AUTOSAR XML (schema 4-2-2)
package /UAES/ASW
  swc implementation Implementation: programming-language=C, sw-version=1.258.1, used-code-generator=Embedded Coder 7.1 (R2018b) 24-May-2018, vendor-id=0, behavior=InternalBehavior
    code-descriptors:
      code Code
        artifact-descriptors:
          short-label=Win_Ctrl_c, category=SWSRC
          short-label=plook_u32u8_even0cka_c, category=SWSRC
          short-label=Win_Ctrl_h, category=SWHDR
          short-label=plook_u32u8_even0cka_h, category=SWHDR
          short-label=rtwtypes_h, category=SWHDR
    resource consumption RsrcCons_Win_Ctrl
package /UAES/ASW/SwComponentTypes
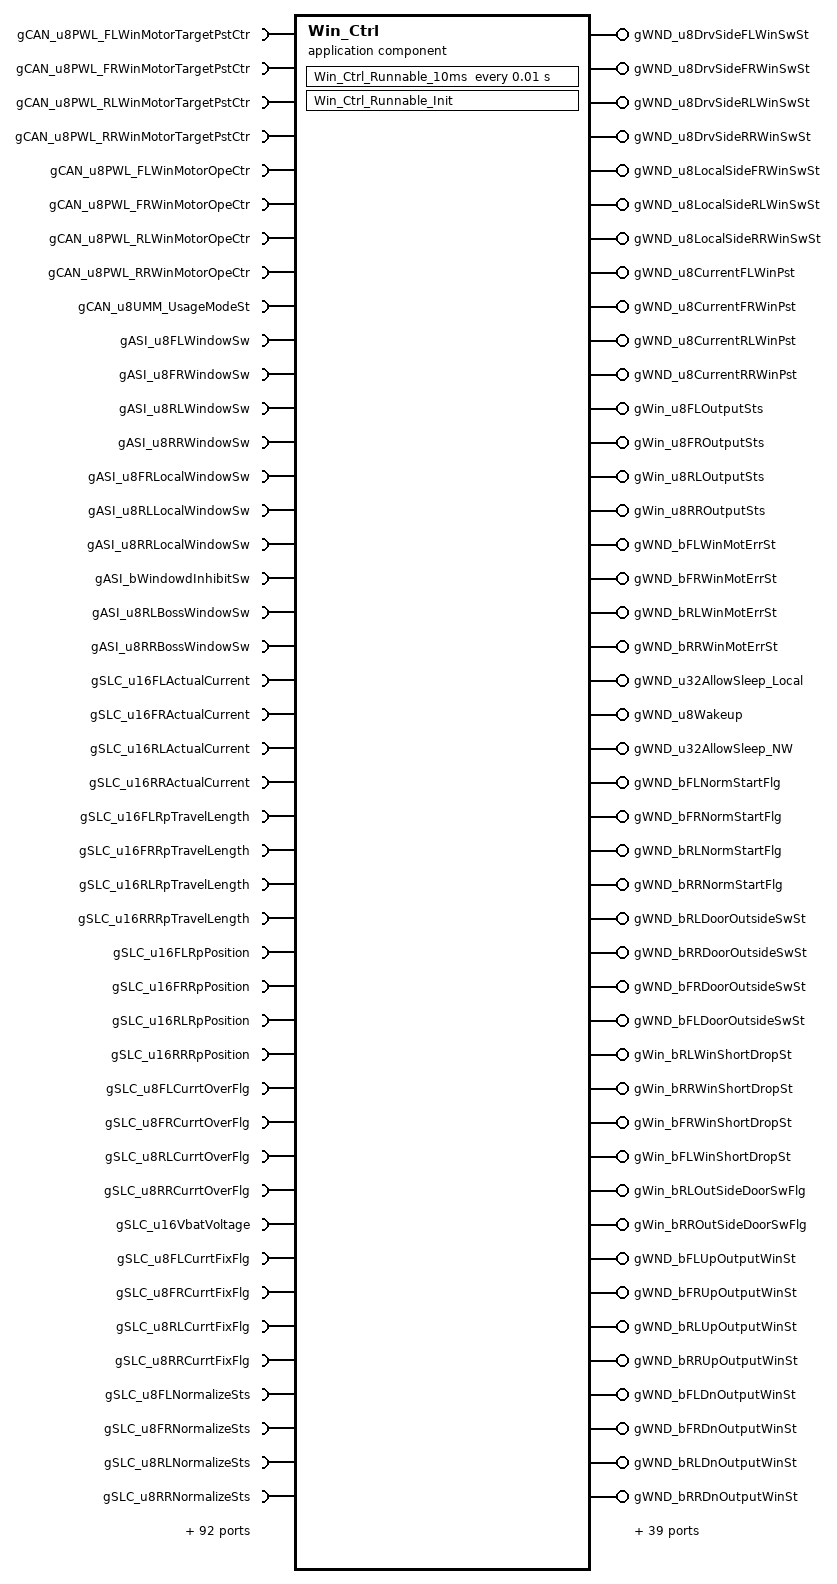
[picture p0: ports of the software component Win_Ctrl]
  application sw component type Win_Ctrl
    136 x require port:
      gCAN_u8PWL_FLWinMotorTargetPstCtr: nonqueued-receiver-com-spec{data-element=gCAN_u8PWL_FLWinMotorTargetPstCtr/Val, init-value=0}, required-interface=gCAN_u8PWL_FLWinMotorTargetPstCtr
      gCAN_u8PWL_FRWinMotorTargetPstCtr: nonqueued-receiver-com-spec{data-element=gCAN_u8PWL_FRWinMotorTargetPstCtr/Val, init-value=0}, required-interface=gCAN_u8PWL_FRWinMotorTargetPstCtr
      gCAN_u8PWL_RLWinMotorTargetPstCtr: nonqueued-receiver-com-spec{data-element=gCAN_u8PWL_RLWinMotorTargetPstCtr/Val, init-value=0}, required-interface=gCAN_u8PWL_RLWinMotorTargetPstCtr
      gCAN_u8PWL_RRWinMotorTargetPstCtr: nonqueued-receiver-com-spec{data-element=gCAN_u8PWL_RRWinMotorTargetPstCtr/Val, init-value=0}, required-interface=gCAN_u8PWL_RRWinMotorTargetPstCtr
      gCAN_u8PWL_FLWinMotorOpeCtr: nonqueued-receiver-com-spec{data-element=gCAN_u8PWL_FLWinMotorOpeCtr/Val, init-value=0}, required-interface=gCAN_u8PWL_FLWinMotorOpeCtr
      gCAN_u8PWL_FRWinMotorOpeCtr: nonqueued-receiver-com-spec{data-element=gCAN_u8PWL_FRWinMotorOpeCtr/Val, init-value=0}, required-interface=gCAN_u8PWL_FRWinMotorOpeCtr
      gCAN_u8PWL_RLWinMotorOpeCtr: nonqueued-receiver-com-spec{data-element=gCAN_u8PWL_RLWinMotorOpeCtr/Val, init-value=0}, required-interface=gCAN_u8PWL_RLWinMotorOpeCtr
      gCAN_u8PWL_RRWinMotorOpeCtr: nonqueued-receiver-com-spec{data-element=gCAN_u8PWL_RRWinMotorOpeCtr/Val, init-value=0}, required-interface=gCAN_u8PWL_RRWinMotorOpeCtr
      gCAN_u8UMM_UsageModeSt: nonqueued-receiver-com-spec{data-element=gCAN_u8UMM_UsageModeSt/Val, init-value=0}, required-interface=gCAN_u8UMM_UsageModeSt
      gASI_u8FLWindowSw: nonqueued-receiver-com-spec{data-element=gASI_u8FLWindowSw/Val, init-value=0}, required-interface=gASI_u8FLWindowSw
      gASI_u8FRWindowSw: nonqueued-receiver-com-spec{data-element=gASI_u8FRWindowSw/Val, init-value=0}, required-interface=gASI_u8FRWindowSw
      gASI_u8RLWindowSw: nonqueued-receiver-com-spec{data-element=gASI_u8RLWindowSw/Val, init-value=0}, required-interface=gASI_u8RLWindowSw
      gASI_u8RRWindowSw: nonqueued-receiver-com-spec{data-element=gASI_u8RRWindowSw/Val, init-value=0}, required-interface=gASI_u8RRWindowSw
      gASI_u8FRLocalWindowSw: nonqueued-receiver-com-spec{data-element=gASI_u8FRLocalWindowSw/Val, init-value=0}, required-interface=gASI_u8FRLocalWindowSw
      gASI_u8RLLocalWindowSw: nonqueued-receiver-com-spec{data-element=gASI_u8RLLocalWindowSw/Val, init-value=0}, required-interface=gASI_u8RLLocalWindowSw
      gASI_u8RRLocalWindowSw: nonqueued-receiver-com-spec{data-element=gASI_u8RRLocalWindowSw/Val, init-value=0}, required-interface=gASI_u8RRLocalWindowSw
      gASI_bWindowdInhibitSw: nonqueued-receiver-com-spec{data-element=gASI_bWindowdInhibitSw/Val, init-value=0}, required-interface=gASI_bWindowdInhibitSw
      gASI_u8RLBossWindowSw: nonqueued-receiver-com-spec{data-element=gASI_u8RLBossWindowSw/Val, init-value=0}, required-interface=gASI_u8RLBossWindowSw
      gASI_u8RRBossWindowSw: nonqueued-receiver-com-spec{data-element=gASI_u8RRBossWindowSw/Val, init-value=0}, required-interface=gASI_u8RRBossWindowSw
      gSLC_u16FLActualCurrent: nonqueued-receiver-com-spec{data-element=gSLC_u16FLActualCurrent/Val, init-value=0}, required-interface=gSLC_u16FLActualCurrent
      gSLC_u16FRActualCurrent: nonqueued-receiver-com-spec{data-element=gSLC_u16FRActualCurrent/Val, init-value=0}, required-interface=gSLC_u16FRActualCurrent
      gSLC_u16RLActualCurrent: nonqueued-receiver-com-spec{data-element=gSLC_u16RLActualCurrent/Val, init-value=0}, required-interface=gSLC_u16RLActualCurrent
      gSLC_u16RRActualCurrent: nonqueued-receiver-com-spec{data-element=gSLC_u16RRActualCurrent/Val, init-value=0}, required-interface=gSLC_u16RRActualCurrent
      gSLC_u16FLRpTravelLength: nonqueued-receiver-com-spec{data-element=gSLC_u16FLRpTravelLength/Val, init-value=0}, required-interface=gSLC_u16FLRpTravelLength
      gSLC_u16FRRpTravelLength: nonqueued-receiver-com-spec{data-element=gSLC_u16FRRpTravelLength/Val, init-value=0}, required-interface=gSLC_u16FRRpTravelLength
      gSLC_u16RLRpTravelLength: nonqueued-receiver-com-spec{data-element=gSLC_u16RLRpTravelLength/Val, init-value=0}, required-interface=gSLC_u16RLRpTravelLength
      gSLC_u16RRRpTravelLength: nonqueued-receiver-com-spec{data-element=gSLC_u16RRRpTravelLength/Val, init-value=0}, required-interface=gSLC_u16RRRpTravelLength
      gSLC_u16FLRpPosition: nonqueued-receiver-com-spec{data-element=gSLC_u16FLRpPosition/Val, init-value=0}, required-interface=gSLC_u16FLRpPosition
      gSLC_u16FRRpPosition: nonqueued-receiver-com-spec{data-element=gSLC_u16FRRpPosition/Val, init-value=0}, required-interface=gSLC_u16FRRpPosition
      gSLC_u16RLRpPosition: nonqueued-receiver-com-spec{data-element=gSLC_u16RLRpPosition/Val, init-value=0}, required-interface=gSLC_u16RLRpPosition
      gSLC_u16RRRpPosition: nonqueued-receiver-com-spec{data-element=gSLC_u16RRRpPosition/Val, init-value=0}, required-interface=gSLC_u16RRRpPosition
      gSLC_u8FLCurrtOverFlg: nonqueued-receiver-com-spec{data-element=gSLC_u8FLCurrtOverFlg/Val, init-value=0}, required-interface=gSLC_u8FLCurrtOverFlg
      gSLC_u8FRCurrtOverFlg: nonqueued-receiver-com-spec{data-element=gSLC_u8FRCurrtOverFlg/Val, init-value=0}, required-interface=gSLC_u8FRCurrtOverFlg
      gSLC_u8RLCurrtOverFlg: nonqueued-receiver-com-spec{data-element=gSLC_u8RLCurrtOverFlg/Val, init-value=0}, required-interface=gSLC_u8RLCurrtOverFlg
      gSLC_u8RRCurrtOverFlg: nonqueued-receiver-com-spec{data-element=gSLC_u8RRCurrtOverFlg/Val, init-value=0}, required-interface=gSLC_u8RRCurrtOverFlg
      gSLC_u16VbatVoltage: nonqueued-receiver-com-spec{data-element=gSLC_u16VbatVoltage/Val, init-value=0}, required-interface=gSLC_u16VbatVoltage
      gSLC_u8FLCurrtFixFlg: nonqueued-receiver-com-spec{data-element=gSLC_u8FLCurrtFixFlg/Val, init-value=0}, required-interface=gSLC_u8FLCurrtFixFlg
      gSLC_u8FRCurrtFixFlg: nonqueued-receiver-com-spec{data-element=gSLC_u8FRCurrtFixFlg/Val, init-value=0}, required-interface=gSLC_u8FRCurrtFixFlg
      gSLC_u8RLCurrtFixFlg: nonqueued-receiver-com-spec{data-element=gSLC_u8RLCurrtFixFlg/Val, init-value=0}, required-interface=gSLC_u8RLCurrtFixFlg
      gSLC_u8RRCurrtFixFlg: nonqueued-receiver-com-spec{data-element=gSLC_u8RRCurrtFixFlg/Val, init-value=0}, required-interface=gSLC_u8RRCurrtFixFlg
      gSLC_u8FLNormalizeSts: nonqueued-receiver-com-spec{data-element=gSLC_u8FLNormalizeSts/Val, init-value=0}, required-interface=gSLC_u8FLNormalizeSts
      gSLC_u8FRNormalizeSts: nonqueued-receiver-com-spec{data-element=gSLC_u8FRNormalizeSts/Val, init-value=0}, required-interface=gSLC_u8FRNormalizeSts
      gSLC_u8RLNormalizeSts: nonqueued-receiver-com-spec{data-element=gSLC_u8RLNormalizeSts/Val, init-value=0}, required-interface=gSLC_u8RLNormalizeSts
      gSLC_u8RRNormalizeSts: nonqueued-receiver-com-spec{data-element=gSLC_u8RRNormalizeSts/Val, init-value=0}, required-interface=gSLC_u8RRNormalizeSts
      gSLC_bFLAPHappen: nonqueued-receiver-com-spec{data-element=gSLC_bFLAPHappen/Val, init-value=0}, required-interface=gSLC_bFLAPHappen
      gSLC_bFRAPHappen: nonqueued-receiver-com-spec{data-element=gSLC_bFRAPHappen/Val, init-value=0}, required-interface=gSLC_bFRAPHappen
      gSLC_bRLAPHappen: nonqueued-receiver-com-spec{data-element=gSLC_bRLAPHappen/Val, init-value=0}, required-interface=gSLC_bRLAPHappen
      gSLC_bRRAPHappen: nonqueued-receiver-com-spec{data-element=gSLC_bRRAPHappen/Val, init-value=0}, required-interface=gSLC_bRRAPHappen
      gSLC_bFLTDCSStopReq: nonqueued-receiver-com-spec{data-element=gSLC_bFLTDCSStopReq/Val, init-value=0}, required-interface=gSLC_bFLTDCSStopReq
      gSLC_bFRTDCSStopReq: nonqueued-receiver-com-spec{data-element=gSLC_bFRTDCSStopReq/Val, init-value=0}, required-interface=gSLC_bFRTDCSStopReq
      gSLC_bRLTDCSStopReq: nonqueued-receiver-com-spec{data-element=gSLC_bRLTDCSStopReq/Val, init-value=0}, required-interface=gSLC_bRLTDCSStopReq
      gSLC_bRRTDCSStopReq: nonqueued-receiver-com-spec{data-element=gSLC_bRRTDCSStopReq/Val, init-value=0}, required-interface=gSLC_bRRTDCSStopReq
      gSLC_bFLBDCSStopReq: nonqueued-receiver-com-spec{data-element=gSLC_bFLBDCSStopReq/Val, init-value=0}, required-interface=gSLC_bFLBDCSStopReq
      gSLC_bFRBDCSStopReq: nonqueued-receiver-com-spec{data-element=gSLC_bFRBDCSStopReq/Val, init-value=0}, required-interface=gSLC_bFRBDCSStopReq
      gSLC_bRLBDCSStopReq: nonqueued-receiver-com-spec{data-element=gSLC_bRLBDCSStopReq/Val, init-value=0}, required-interface=gSLC_bRLBDCSStopReq
      gSLC_bRRBDCSStopReq: nonqueued-receiver-com-spec{data-element=gSLC_bRRBDCSStopReq/Val, init-value=0}, required-interface=gSLC_bRRBDCSStopReq
      gSLC_bFLIsInAPRange: nonqueued-receiver-com-spec{data-element=gSLC_bFLIsInAPRange/Val, init-value=0}, required-interface=gSLC_bFLIsInAPRange
      gSLC_bFRIsInAPRange: nonqueued-receiver-com-spec{data-element=gSLC_bFRIsInAPRange/Val, init-value=0}, required-interface=gSLC_bFRIsInAPRange
      gSLC_bRLIsInAPRange: nonqueued-receiver-com-spec{data-element=gSLC_bRLIsInAPRange/Val, init-value=0}, required-interface=gSLC_bRLIsInAPRange
      gSLC_bRRIsInAPRange: nonqueued-receiver-com-spec{data-element=gSLC_bRRIsInAPRange/Val, init-value=0}, required-interface=gSLC_bRRIsInAPRange
      gSLC_bFLPositionLostFlg: nonqueued-receiver-com-spec{data-element=gSLC_bFLPositionLostFlg/Val, init-value=0}, required-interface=gSLC_bFLPositionLostFlg
      gSLC_bFRPositionLostFlg: nonqueued-receiver-com-spec{data-element=gSLC_bFRPositionLostFlg/Val, init-value=0}, required-interface=gSLC_bFRPositionLostFlg
      gSLC_bRLPositionLostFlg: nonqueued-receiver-com-spec{data-element=gSLC_bRLPositionLostFlg/Val, init-value=0}, required-interface=gSLC_bRLPositionLostFlg
      gSLC_bRRPositionLostFlg: nonqueued-receiver-com-spec{data-element=gSLC_bRRPositionLostFlg/Val, init-value=0}, required-interface=gSLC_bRRPositionLostFlg
      gDoor_bFLDoorAjarSt: nonqueued-receiver-com-spec{data-element=gDoor_bFLDoorAjarSt/Val, init-value=0}, required-interface=gDoor_bFLDoorAjarSt
      gDoor_bFRDoorAjarSt: nonqueued-receiver-com-spec{data-element=gDoor_bFRDoorAjarSt/Val, init-value=0}, required-interface=gDoor_bFRDoorAjarSt
      gDoor_bRLDoorAjarSt: nonqueued-receiver-com-spec{data-element=gDoor_bRLDoorAjarSt/Val, init-value=0}, required-interface=gDoor_bRLDoorAjarSt
      gDoor_bRRDoorAjarSt: nonqueued-receiver-com-spec{data-element=gDoor_bRRDoorAjarSt/Val, init-value=0}, required-interface=gDoor_bRRDoorAjarSt
      gASI_bRLDoorHSUSw: nonqueued-receiver-com-spec{data-element=gASI_bRLDoorHSUSw/Val, init-value=0}, required-interface=gASI_bRLDoorHSUSw
      gASI_bRRDoorHSUSw: nonqueued-receiver-com-spec{data-element=gASI_bRRDoorHSUSw/Val, init-value=0}, required-interface=gASI_bRRDoorHSUSw
      gASI_bFLDoorHSUSw: nonqueued-receiver-com-spec{data-element=gASI_bFLDoorHSUSw/Val, init-value=0}, required-interface=gASI_bFLDoorHSUSw
      gASI_bFRDoorHSUSw: nonqueued-receiver-com-spec{data-element=gASI_bFRDoorHSUSw/Val, init-value=0}, required-interface=gASI_bFRDoorHSUSw
      gLock_bRLDoorLockFbSt: nonqueued-receiver-com-spec{data-element=gLock_bRLDoorLockFbSt/Val, init-value=0}, required-interface=gLock_bRLDoorLockFbSt
      gLock_bRRDoorLockFbSt: nonqueued-receiver-com-spec{data-element=gLock_bRRDoorLockFbSt/Val, init-value=0}, required-interface=gLock_bRRDoorLockFbSt
      gLock_bFLDoorLockFbSt: nonqueued-receiver-com-spec{data-element=gLock_bFLDoorLockFbSt/Val, init-value=0}, required-interface=gLock_bFLDoorLockFbSt
      gLock_bFRDoorLockFbSt: nonqueued-receiver-com-spec{data-element=gLock_bFRDoorLockFbSt/Val, init-value=0}, required-interface=gLock_bFRDoorLockFbSt
      gCFG_bFLDoorFramelessGlassCfg: nonqueued-receiver-com-spec{data-element=gCFG_bFLDoorFramelessGlassCfg/Val, init-value=0}, required-interface=gCFG_bFLDoorFramelessGlassCfg
      gCFG_bFRDoorFramelessGlassCfg: nonqueued-receiver-com-spec{data-element=gCFG_bFRDoorFramelessGlassCfg/Val, init-value=0}, required-interface=gCFG_bFRDoorFramelessGlassCfg
      gCFG_bRLDoorFramelessGlassCfg: nonqueued-receiver-com-spec{data-element=gCFG_bRLDoorFramelessGlassCfg/Val, init-value=0}, required-interface=gCFG_bRLDoorFramelessGlassCfg
      gCFG_bRRDoorFramelessGlassCfg: nonqueued-receiver-com-spec{data-element=gCFG_bRRDoorFramelessGlassCfg/Val, init-value=0}, required-interface=gCFG_bRRDoorFramelessGlassCfg
      gCAN_u8POD_FLWinShortDropCmd: nonqueued-receiver-com-spec{data-element=gCAN_u8POD_FLWinShortDropCmd/Val, init-value=0}, required-interface=gCAN_u8POD_FLWinShortDropCmd
      gCAN_u8POD_FRWinShortDropCmd: nonqueued-receiver-com-spec{data-element=gCAN_u8POD_FRWinShortDropCmd/Val, init-value=0}, required-interface=gCAN_u8POD_FRWinShortDropCmd
      gCAN_u8POD_RLWinShortDropCmd: nonqueued-receiver-com-spec{data-element=gCAN_u8POD_RLWinShortDropCmd/Val, init-value=0}, required-interface=gCAN_u8POD_RLWinShortDropCmd
      gCAN_u8POD_RRWinShortDropCmd: nonqueued-receiver-com-spec{data-element=gCAN_u8POD_RRWinShortDropCmd/Val, init-value=0}, required-interface=gCAN_u8POD_RRWinShortDropCmd
      gCFG_u8PwrRelsType: nonqueued-receiver-com-spec{data-element=gCFG_u8PwrRelsType/Val, init-value=0}, required-interface=gCFG_u8PwrRelsType
      gCFG_bWndVentilationFunCfg: nonqueued-receiver-com-spec{data-element=gCFG_bWndVentilationFunCfg/Val, init-value=0}, required-interface=gCFG_bWndVentilationFunCfg
      gPRM_u8WndVentilationPst: nonqueued-receiver-com-spec{data-element=gPRM_u8WndVentilationPst/Val, init-value=0}, required-interface=gPRM_u8WndVentilationPst
      gPRM_u8WndLckLEDPWM_Lv1: nonqueued-receiver-com-spec{data-element=gPRM_u8WndLckLEDPWM_Lv1/Val, init-value=0}, required-interface=gPRM_u8WndLckLEDPWM_Lv1
      gPRM_u8WndLckLEDPWM_Lv2: nonqueued-receiver-com-spec{data-element=gPRM_u8WndLckLEDPWM_Lv2/Val, init-value=0}, required-interface=gPRM_u8WndLckLEDPWM_Lv2
      gPRM_u8FLWinShortDropPst: nonqueued-receiver-com-spec{data-element=gPRM_u8FLWinShortDropPst/Val, init-value=0}, required-interface=gPRM_u8FLWinShortDropPst
      gPRM_u8FRWinShortDropPst: nonqueued-receiver-com-spec{data-element=gPRM_u8FRWinShortDropPst/Val, init-value=0}, required-interface=gPRM_u8FRWinShortDropPst
      gPRM_u8RLWinShortDropPst: nonqueued-receiver-com-spec{data-element=gPRM_u8RLWinShortDropPst/Val, init-value=0}, required-interface=gPRM_u8RLWinShortDropPst
      gPRM_u8RRWinShortDropPst: nonqueued-receiver-com-spec{data-element=gPRM_u8RRWinShortDropPst/Val, init-value=0}, required-interface=gPRM_u8RRWinShortDropPst
      gPRM_u8FLPowerDoorReqWinOpenPst: nonqueued-receiver-com-spec{data-element=gPRM_u8FLPowerDoorReqWinOpenPst/Val, init-value=0}, required-interface=gPRM_u8FLPowerDoorReqWinOpenPst
      gPRM_u8FRPowerDoorReqWinOpenPst: nonqueued-receiver-com-spec{data-element=gPRM_u8FRPowerDoorReqWinOpenPst/Val, init-value=0}, required-interface=gPRM_u8FRPowerDoorReqWinOpenPst
      gPRM_u8RLPowerDoorReqWinOpenPst: nonqueued-receiver-com-spec{data-element=gPRM_u8RLPowerDoorReqWinOpenPst/Val, init-value=0}, required-interface=gPRM_u8RLPowerDoorReqWinOpenPst
      gPRM_u8RRPowerDoorReqWinOpenPst: nonqueued-receiver-com-spec{data-element=gPRM_u8RRPowerDoorReqWinOpenPst/Val, init-value=0}, required-interface=gPRM_u8RRPowerDoorReqWinOpenPst
      gPRM_bPODRelsCinchFunEnCfgFL: nonqueued-receiver-com-spec{data-element=gPRM_bPODRelsCinchFunEnCfgFL/Val, init-value=0}, required-interface=gPRM_bPODRelsCinchFunEnCfgFL
      gPRM_bPODRelsCinchFunEnCfgFR: nonqueued-receiver-com-spec{data-element=gPRM_bPODRelsCinchFunEnCfgFR/Val, init-value=0}, required-interface=gPRM_bPODRelsCinchFunEnCfgFR
      gPRM_bPODRelsCinchFunEnCfgRL: nonqueued-receiver-com-spec{data-element=gPRM_bPODRelsCinchFunEnCfgRL/Val, init-value=0}, required-interface=gPRM_bPODRelsCinchFunEnCfgRL
      gPRM_bPODRelsCinchFunEnCfgRR: nonqueued-receiver-com-spec{data-element=gPRM_bPODRelsCinchFunEnCfgRR/Val, init-value=0}, required-interface=gPRM_bPODRelsCinchFunEnCfgRR
      gDCU_bFLReverseFlag: nonqueued-receiver-com-spec{data-element=gDCU_bFLReverseFlag/Val, init-value=0}, required-interface=gDCU_bFLReverseFlag
      gDCU_bFRReverseFlag: nonqueued-receiver-com-spec{data-element=gDCU_bFRReverseFlag/Val, init-value=0}, required-interface=gDCU_bFRReverseFlag
      gDCU_bRLReverseFlag: nonqueued-receiver-com-spec{data-element=gDCU_bRLReverseFlag/Val, init-value=0}, required-interface=gDCU_bRLReverseFlag
      gDCU_bRRReverseFlag: nonqueued-receiver-com-spec{data-element=gDCU_bRRReverseFlag/Val, init-value=0}, required-interface=gDCU_bRRReverseFlag
      gASI_bCCULostCommon: nonqueued-receiver-com-spec{data-element=gASI_bCCULostCommon/Val, init-value=0}, required-interface=gASI_bCCULostCommon
      gASI_bPowerOnReset: nonqueued-receiver-com-spec{data-element=gASI_bPowerOnReset/Val, init-value=0}, required-interface=gASI_bPowerOnReset
      gVRM_u16BatteryVolt_mv: nonqueued-receiver-com-spec{data-element=gVRM_u16BatteryVolt_mv/Val, init-value=0}, required-interface=gVRM_u16BatteryVolt_mv
      gSLC_bFLActiveFlg: nonqueued-receiver-com-spec{data-element=gSLC_bFLActiveFlg/Val, init-value=0}, required-interface=gSLC_bFLActiveFlg
      gSLC_bFRActiveFlg: nonqueued-receiver-com-spec{data-element=gSLC_bFRActiveFlg/Val, init-value=0}, required-interface=gSLC_bFRActiveFlg
      gSLC_bRLActiveFlg: nonqueued-receiver-com-spec{data-element=gSLC_bRLActiveFlg/Val, init-value=0}, required-interface=gSLC_bRLActiveFlg
      gSLC_bRRActiveFlg: nonqueued-receiver-com-spec{data-element=gSLC_bRRActiveFlg/Val, init-value=0}, required-interface=gSLC_bRRActiveFlg
      gDCU_bFLWinUpOutput: nonqueued-receiver-com-spec{data-element=gDCU_bFLWinUpOutput/Val, init-value=0}, required-interface=gDCU_bFLWinUpOutput
      gDCU_bFLWinDownOutput: nonqueued-receiver-com-spec{data-element=gDCU_bFLWinDownOutput/Val, init-value=0}, required-interface=gDCU_bFLWinDownOutput
      gDCU_bFRWinUpOutput: nonqueued-receiver-com-spec{data-element=gDCU_bFRWinUpOutput/Val, init-value=0}, required-interface=gDCU_bFRWinUpOutput
      gDCU_bFRWinDownOutput: nonqueued-receiver-com-spec{data-element=gDCU_bFRWinDownOutput/Val, init-value=0}, required-interface=gDCU_bFRWinDownOutput
      gDCU_bRLWinUpOutput: nonqueued-receiver-com-spec{data-element=gDCU_bRLWinUpOutput/Val, init-value=0}, required-interface=gDCU_bRLWinUpOutput
      gDCU_bRLWinDownOutput: nonqueued-receiver-com-spec{data-element=gDCU_bRLWinDownOutput/Val, init-value=0}, required-interface=gDCU_bRLWinDownOutput
      gDCU_bRRWinUpOutput: nonqueued-receiver-com-spec{data-element=gDCU_bRRWinUpOutput/Val, init-value=0}, required-interface=gDCU_bRRWinUpOutput
      gDCU_bRRWinDownOutput: nonqueued-receiver-com-spec{data-element=gDCU_bRRWinDownOutput/Val, init-value=0}, required-interface=gDCU_bRRWinDownOutput
      gWin_bFLSwStuckFlg: nonqueued-receiver-com-spec{data-element=gWin_bFLSwStuckFlg/Val, init-value=0}, required-interface=gWin_bFLSwStuckFlg
      gWin_bFRSwStuckFlg: nonqueued-receiver-com-spec{data-element=gWin_bFRSwStuckFlg/Val, init-value=0}, required-interface=gWin_bFRSwStuckFlg
      gWin_bRLSwStuckFlg: nonqueued-receiver-com-spec{data-element=gWin_bRLSwStuckFlg/Val, init-value=0}, required-interface=gWin_bRLSwStuckFlg
      gWin_bRRSwStuckFlg: nonqueued-receiver-com-spec{data-element=gWin_bRRSwStuckFlg/Val, init-value=0}, required-interface=gWin_bRRSwStuckFlg
      gCAN_bPWL_FLWinRelearnReq: nonqueued-receiver-com-spec{data-element=gCAN_bPWL_FLWinRelearnReq/Val, init-value=0}, required-interface=gCAN_bPWL_FLWinRelearnReq
      gCAN_bPWL_FRWinRelearnReq: nonqueued-receiver-com-spec{data-element=gCAN_bPWL_FRWinRelearnReq/Val, init-value=0}, required-interface=gCAN_bPWL_FRWinRelearnReq
      gCAN_bPWL_RLWinRelearnReq: nonqueued-receiver-com-spec{data-element=gCAN_bPWL_RLWinRelearnReq/Val, init-value=0}, required-interface=gCAN_bPWL_RLWinRelearnReq
      gCAN_bPWL_RRWinRelearnReq: nonqueued-receiver-com-spec{data-element=gCAN_bPWL_RRWinRelearnReq/Val, init-value=0}, required-interface=gCAN_bPWL_RRWinRelearnReq
      gCFG_u8LocalSideWinSwType: nonqueued-receiver-com-spec{data-element=gCFG_u8LocalSideWinSwType/Val, init-value=0}, required-interface=gCFG_u8LocalSideWinSwType
      gCFG_u8DriverSideWinSwType: nonqueued-receiver-com-spec{data-element=gCFG_u8DriverSideWinSwType/Val, init-value=0}, required-interface=gCFG_u8DriverSideWinSwType
      gPRM_u8UINM_DriverSideWinSwActivetime: nonqueued-receiver-com-spec{data-element=gPRM_u8UINM_DriverSideWinSwActivetime/Val, init-value=0}, required-interface=gPRM_u8UINM_DriverSideWinSwActivetime
      gPRM_u8UINM_LocalSideWinSwActivetime: nonqueued-receiver-com-spec{data-element=gPRM_u8UINM_LocalSideWinSwActivetime/Val, init-value=0}, required-interface=gPRM_u8UINM_LocalSideWinSwActivetime
      gWND_u8DrvWinOutput: nonqueued-receiver-com-spec{data-element=gWND_u8DrvWinOutput/Val, init-value=0}, required-interface=gWND_u8DrvWinOutput
      gWND_u8PsgWinOutput: nonqueued-receiver-com-spec{data-element=gWND_u8PsgWinOutput/Val, init-value=0}, required-interface=gWND_u8PsgWinOutput
      gWND_u8RLWinOutput: nonqueued-receiver-com-spec{data-element=gWND_u8RLWinOutput/Val, init-value=0}, required-interface=gWND_u8RLWinOutput
      gWND_u8RRWinOutput: nonqueued-receiver-com-spec{data-element=gWND_u8RRWinOutput/Val, init-value=0}, required-interface=gWND_u8RRWinOutput
    83 x provide port:
      gWND_u8DrvSideFLWinSwSt: nonqueued-sender-com-spec{data-element=gWND_u8DrvSideFLWinSwSt/Val, init-value=0}, provided-interface=gWND_u8DrvSideFLWinSwSt
      gWND_u8DrvSideFRWinSwSt: nonqueued-sender-com-spec{data-element=gWND_u8DrvSideFRWinSwSt/Val, init-value=0}, provided-interface=gWND_u8DrvSideFRWinSwSt
      gWND_u8DrvSideRLWinSwSt: nonqueued-sender-com-spec{data-element=gWND_u8DrvSideRLWinSwSt/Val, init-value=0}, provided-interface=gWND_u8DrvSideRLWinSwSt
      gWND_u8DrvSideRRWinSwSt: nonqueued-sender-com-spec{data-element=gWND_u8DrvSideRRWinSwSt/Val, init-value=0}, provided-interface=gWND_u8DrvSideRRWinSwSt
      gWND_u8LocalSideFRWinSwSt: nonqueued-sender-com-spec{data-element=gWND_u8LocalSideFRWinSwSt/Val, init-value=0}, provided-interface=gWND_u8LocalSideFRWinSwSt
      gWND_u8LocalSideRLWinSwSt: nonqueued-sender-com-spec{data-element=gWND_u8LocalSideRLWinSwSt/Val, init-value=0}, provided-interface=gWND_u8LocalSideRLWinSwSt
      gWND_u8LocalSideRRWinSwSt: nonqueued-sender-com-spec{data-element=gWND_u8LocalSideRRWinSwSt/Val, init-value=0}, provided-interface=gWND_u8LocalSideRRWinSwSt
      gWND_u8CurrentFLWinPst: nonqueued-sender-com-spec{data-element=gWND_u8CurrentFLWinPst/Val, init-value=0}, provided-interface=gWND_u8CurrentFLWinPst
      gWND_u8CurrentFRWinPst: nonqueued-sender-com-spec{data-element=gWND_u8CurrentFRWinPst/Val, init-value=0}, provided-interface=gWND_u8CurrentFRWinPst
      gWND_u8CurrentRLWinPst: nonqueued-sender-com-spec{data-element=gWND_u8CurrentRLWinPst/Val, init-value=0}, provided-interface=gWND_u8CurrentRLWinPst
      gWND_u8CurrentRRWinPst: nonqueued-sender-com-spec{data-element=gWND_u8CurrentRRWinPst/Val, init-value=0}, provided-interface=gWND_u8CurrentRRWinPst
      gWin_u8FLOutputSts: nonqueued-sender-com-spec{data-element=gWin_u8FLOutputSts/Val, init-value=0}, provided-interface=gWin_u8FLOutputSts
      gWin_u8FROutputSts: nonqueued-sender-com-spec{data-element=gWin_u8FROutputSts/Val, init-value=0}, provided-interface=gWin_u8FROutputSts
      gWin_u8RLOutputSts: nonqueued-sender-com-spec{data-element=gWin_u8RLOutputSts/Val, init-value=0}, provided-interface=gWin_u8RLOutputSts
      gWin_u8RROutputSts: nonqueued-sender-com-spec{data-element=gWin_u8RROutputSts/Val, init-value=0}, provided-interface=gWin_u8RROutputSts
      gWND_bFLWinMotErrSt: nonqueued-sender-com-spec{data-element=gWND_bFLWinMotErrSt/Val, init-value=0}, provided-interface=gWND_bFLWinMotErrSt
      gWND_bFRWinMotErrSt: nonqueued-sender-com-spec{data-element=gWND_bFRWinMotErrSt/Val, init-value=0}, provided-interface=gWND_bFRWinMotErrSt
      gWND_bRLWinMotErrSt: nonqueued-sender-com-spec{data-element=gWND_bRLWinMotErrSt/Val, init-value=0}, provided-interface=gWND_bRLWinMotErrSt
      gWND_bRRWinMotErrSt: nonqueued-sender-com-spec{data-element=gWND_bRRWinMotErrSt/Val, init-value=0}, provided-interface=gWND_bRRWinMotErrSt
      gWND_u32AllowSleep_Local: nonqueued-sender-com-spec{data-element=gWND_u32AllowSleep_Local/Val, init-value=0}, provided-interface=gWND_u32AllowSleep_Local
      gWND_u8Wakeup: nonqueued-sender-com-spec{data-element=gWND_u8Wakeup/Val, init-value=0}, provided-interface=gWND_u8Wakeup
      gWND_u32AllowSleep_NW: nonqueued-sender-com-spec{data-element=gWND_u32AllowSleep_NW/Val, init-value=0}, provided-interface=gWND_u32AllowSleep_NW
      gWND_bFLNormStartFlg: nonqueued-sender-com-spec{data-element=gWND_bFLNormStartFlg/Val, init-value=0}, provided-interface=gWND_bFLNormStartFlg
      gWND_bFRNormStartFlg: nonqueued-sender-com-spec{data-element=gWND_bFRNormStartFlg/Val, init-value=0}, provided-interface=gWND_bFRNormStartFlg
      gWND_bRLNormStartFlg: nonqueued-sender-com-spec{data-element=gWND_bRLNormStartFlg/Val, init-value=0}, provided-interface=gWND_bRLNormStartFlg
      gWND_bRRNormStartFlg: nonqueued-sender-com-spec{data-element=gWND_bRRNormStartFlg/Val, init-value=0}, provided-interface=gWND_bRRNormStartFlg
      gWND_bRLDoorOutsideSwSt: nonqueued-sender-com-spec{data-element=gWND_bRLDoorOutsideSwSt/Val, init-value=0}, provided-interface=gWND_bRLDoorOutsideSwSt
      gWND_bRRDoorOutsideSwSt: nonqueued-sender-com-spec{data-element=gWND_bRRDoorOutsideSwSt/Val, init-value=0}, provided-interface=gWND_bRRDoorOutsideSwSt
      gWND_bFRDoorOutsideSwSt: nonqueued-sender-com-spec{data-element=gWND_bFRDoorOutsideSwSt/Val, init-value=0}, provided-interface=gWND_bFRDoorOutsideSwSt
      gWND_bFLDoorOutsideSwSt: nonqueued-sender-com-spec{data-element=gWND_bFLDoorOutsideSwSt/Val, init-value=0}, provided-interface=gWND_bFLDoorOutsideSwSt
      gWin_bRLWinShortDropSt: nonqueued-sender-com-spec{data-element=gWin_bRLWinShortDropSt/Val, init-value=0}, provided-interface=gWin_bRLWinShortDropSt
      gWin_bRRWinShortDropSt: nonqueued-sender-com-spec{data-element=gWin_bRRWinShortDropSt/Val, init-value=0}, provided-interface=gWin_bRRWinShortDropSt
      gWin_bFRWinShortDropSt: nonqueued-sender-com-spec{data-element=gWin_bFRWinShortDropSt/Val, init-value=0}, provided-interface=gWin_bFRWinShortDropSt
      gWin_bFLWinShortDropSt: nonqueued-sender-com-spec{data-element=gWin_bFLWinShortDropSt/Val, init-value=0}, provided-interface=gWin_bFLWinShortDropSt
      gWin_bRLOutSideDoorSwFlg: nonqueued-sender-com-spec{data-element=gWin_bRLOutSideDoorSwFlg/Val, init-value=0}, provided-interface=gWin_bRLOutSideDoorSwFlg
      gWin_bRROutSideDoorSwFlg: nonqueued-sender-com-spec{data-element=gWin_bRROutSideDoorSwFlg/Val, init-value=0}, provided-interface=gWin_bRROutSideDoorSwFlg
      gWND_bFLUpOutputWinSt: nonqueued-sender-com-spec{data-element=gWND_bFLUpOutputWinSt/Val, init-value=0}, provided-interface=gWND_bFLUpOutputWinSt
      gWND_bFRUpOutputWinSt: nonqueued-sender-com-spec{data-element=gWND_bFRUpOutputWinSt/Val, init-value=0}, provided-interface=gWND_bFRUpOutputWinSt
      gWND_bRLUpOutputWinSt: nonqueued-sender-com-spec{data-element=gWND_bRLUpOutputWinSt/Val, init-value=0}, provided-interface=gWND_bRLUpOutputWinSt
      gWND_bRRUpOutputWinSt: nonqueued-sender-com-spec{data-element=gWND_bRRUpOutputWinSt/Val, init-value=0}, provided-interface=gWND_bRRUpOutputWinSt
      gWND_bFLDnOutputWinSt: nonqueued-sender-com-spec{data-element=gWND_bFLDnOutputWinSt/Val, init-value=0}, provided-interface=gWND_bFLDnOutputWinSt
      gWND_bFRDnOutputWinSt: nonqueued-sender-com-spec{data-element=gWND_bFRDnOutputWinSt/Val, init-value=0}, provided-interface=gWND_bFRDnOutputWinSt
      gWND_bRLDnOutputWinSt: nonqueued-sender-com-spec{data-element=gWND_bRLDnOutputWinSt/Val, init-value=0}, provided-interface=gWND_bRLDnOutputWinSt
      gWND_bRRDnOutputWinSt: nonqueued-sender-com-spec{data-element=gWND_bRRDnOutputWinSt/Val, init-value=0}, provided-interface=gWND_bRRDnOutputWinSt
      gWND_u8FLPositionSts: nonqueued-sender-com-spec{data-element=gWND_u8FLPositionSts/Val, init-value=0}, provided-interface=gWND_u8FLPositionSts
      gWND_u8FRPositionSts: nonqueued-sender-com-spec{data-element=gWND_u8FRPositionSts/Val, init-value=0}, provided-interface=gWND_u8FRPositionSts
      gWND_u8RLPositionSts: nonqueued-sender-com-spec{data-element=gWND_u8RLPositionSts/Val, init-value=0}, provided-interface=gWND_u8RLPositionSts
      gWND_u8RRPositionSts: nonqueued-sender-com-spec{data-element=gWND_u8RRPositionSts/Val, init-value=0}, provided-interface=gWND_u8RRPositionSts
      gWin_bFLOutSideDoorSwFlg: nonqueued-sender-com-spec{data-element=gWin_bFLOutSideDoorSwFlg/Val, init-value=0}, provided-interface=gWin_bFLOutSideDoorSwFlg
      gWin_bFROutSideDoorSwFlg: nonqueued-sender-com-spec{data-element=gWin_bFROutSideDoorSwFlg/Val, init-value=0}, provided-interface=gWin_bFROutSideDoorSwFlg
      gWin_u8FLWNDExecReq: nonqueued-sender-com-spec{data-element=gWin_u8FLWNDExecReq/Val, init-value=0}, provided-interface=gWin_u8FLWNDExecReq
      gWin_u8FRWNDExecReq: nonqueued-sender-com-spec{data-element=gWin_u8FRWNDExecReq/Val, init-value=0}, provided-interface=gWin_u8FRWNDExecReq
      gWin_u8RLWNDExecReq: nonqueued-sender-com-spec{data-element=gWin_u8RLWNDExecReq/Val, init-value=0}, provided-interface=gWin_u8RLWNDExecReq
      gWin_u8RRWNDExecReq: nonqueued-sender-com-spec{data-element=gWin_u8RRWNDExecReq/Val, init-value=0}, provided-interface=gWin_u8RRWNDExecReq
      gWin_bAllow_FLSPsleep: nonqueued-sender-com-spec{data-element=gWin_bAllow_FLSPsleep/Val, init-value=0}, provided-interface=gWin_bAllow_FLSPsleep
      gWin_bAllow_FRSPsleep: nonqueued-sender-com-spec{data-element=gWin_bAllow_FRSPsleep/Val, init-value=0}, provided-interface=gWin_bAllow_FRSPsleep
      gWin_bAllow_RLSPsleep: nonqueued-sender-com-spec{data-element=gWin_bAllow_RLSPsleep/Val, init-value=0}, provided-interface=gWin_bAllow_RLSPsleep
      gWin_bAllow_RRSPsleep: nonqueued-sender-com-spec{data-element=gWin_bAllow_RRSPsleep/Val, init-value=0}, provided-interface=gWin_bAllow_RRSPsleep
      gWin_bSpecialFlag_FL: nonqueued-sender-com-spec{data-element=gWin_bSpecialFlag_FL/Val, init-value=0}, provided-interface=gWin_bSpecialFlag_FL
      gWin_bSpecialFlag_FR: nonqueued-sender-com-spec{data-element=gWin_bSpecialFlag_FR/Val, init-value=0}, provided-interface=gWin_bSpecialFlag_FR
      gWin_bSpecialFlag_RL: nonqueued-sender-com-spec{data-element=gWin_bSpecialFlag_RL/Val, init-value=0}, provided-interface=gWin_bSpecialFlag_RL
      gWin_bSpecialFlag_RR: nonqueued-sender-com-spec{data-element=gWin_bSpecialFlag_RR/Val, init-value=0}, provided-interface=gWin_bSpecialFlag_RR
      gWin_u8FLWNDCmd: nonqueued-sender-com-spec{data-element=gWin_u8FLWNDCmd/Val, init-value=0}, provided-interface=gWin_u8FLWNDCmd
      gWin_u8FRWNDCmd: nonqueued-sender-com-spec{data-element=gWin_u8FRWNDCmd/Val, init-value=0}, provided-interface=gWin_u8FRWNDCmd
      gWin_u8RLWNDCmd: nonqueued-sender-com-spec{data-element=gWin_u8RLWNDCmd/Val, init-value=0}, provided-interface=gWin_u8RLWNDCmd
      gWin_u8RRWNDCmd: nonqueued-sender-com-spec{data-element=gWin_u8RRWNDCmd/Val, init-value=0}, provided-interface=gWin_u8RRWNDCmd
      gWin_u8FLWNDCmdSrc: nonqueued-sender-com-spec{data-element=gWin_u8FLWNDCmdSrc/Val, init-value=0}, provided-interface=gWin_u8FLWNDCmdSrc
      gWin_u8FRWNDCmdSrc: nonqueued-sender-com-spec{data-element=gWin_u8FRWNDCmdSrc/Val, init-value=0}, provided-interface=gWin_u8FRWNDCmdSrc
      gWin_u8RLWNDCmdSrc: nonqueued-sender-com-spec{data-element=gWin_u8RLWNDCmdSrc/Val, init-value=0}, provided-interface=gWin_u8RLWNDCmdSrc
      gWin_u8RRWNDCmdSrc: nonqueued-sender-com-spec{data-element=gWin_u8RRWNDCmdSrc/Val, init-value=0}, provided-interface=gWin_u8RRWNDCmdSrc
      gWin_bFLWinShrtDrpFlg: nonqueued-sender-com-spec{data-element=gWin_bFLWinShrtDrpFlg/Val, init-value=0}, provided-interface=gWin_bFLWinShrtDrpFlg
      gWin_bFRWinShrtDrpFlg: nonqueued-sender-com-spec{data-element=gWin_bFRWinShrtDrpFlg/Val, init-value=0}, provided-interface=gWin_bFRWinShrtDrpFlg
      gWin_bRLWinShrtDrpFlg: nonqueued-sender-com-spec{data-element=gWin_bRLWinShrtDrpFlg/Val, init-value=0}, provided-interface=gWin_bRLWinShrtDrpFlg
      gWin_bRRWinShrtDrpFlg: nonqueued-sender-com-spec{data-element=gWin_bRRWinShrtDrpFlg/Val, init-value=0}, provided-interface=gWin_bRRWinShrtDrpFlg
      gWND_bPsgWinLockBtnSt: nonqueued-sender-com-spec{data-element=gWND_bPsgWinLockBtnSt/Val, init-value=0}, provided-interface=gWND_bPsgWinLockBtnSt
      gWin_u8PWL_WinOpeationSt_FLWinSt: nonqueued-sender-com-spec{data-element=gWin_u8PWL_WinOpeationSt_FLWinSt/Val, init-value=0}, provided-interface=gWin_u8PWL_WinOpeationSt_FLWinSt
      gWin_u8PWL_WinOpeationSt_FRWinSt: nonqueued-sender-com-spec{data-element=gWin_u8PWL_WinOpeationSt_FRWinSt/Val, init-value=0}, provided-interface=gWin_u8PWL_WinOpeationSt_FRWinSt
      gWin_u8PWL_WinOpeationSt_RLWinSt: nonqueued-sender-com-spec{data-element=gWin_u8PWL_WinOpeationSt_RLWinSt/Val, init-value=0}, provided-interface=gWin_u8PWL_WinOpeationSt_RLWinSt
      gWin_u8PWL_WinOpeationSt_RRWinSt: nonqueued-sender-com-spec{data-element=gWin_u8PWL_WinOpeationSt_RRWinSt/Val, init-value=0}, provided-interface=gWin_u8PWL_WinOpeationSt_RRWinSt
      gWin_bFLDelayAdjSpdFlg: nonqueued-sender-com-spec{data-element=gWin_bFLDelayAdjSpdFlg/Val, init-value=0}, provided-interface=gWin_bFLDelayAdjSpdFlg
      gWin_bFRDelayAdjSpdFlg: nonqueued-sender-com-spec{data-element=gWin_bFRDelayAdjSpdFlg/Val, init-value=0}, provided-interface=gWin_bFRDelayAdjSpdFlg
      gWin_bRLDelayAdjSpdFlg: nonqueued-sender-com-spec{data-element=gWin_bRLDelayAdjSpdFlg/Val, init-value=0}, provided-interface=gWin_bRLDelayAdjSpdFlg
      gWin_bRRDelayAdjSpdFlg: nonqueued-sender-com-spec{data-element=gWin_bRRDelayAdjSpdFlg/Val, init-value=0}, provided-interface=gWin_bRRDelayAdjSpdFlg
    behavior InternalBehavior: handle-termination-and-restart=NO-SUPPORT
      init event Win_Ctrl_InitEvent: start-on-event=Win_Ctrl_Runnable_Init
      timing event TMT_Win_Ctrl_Runnable_10ms: start-on-event=Win_Ctrl_Runnable_10ms, period=0.01
      runnable Win_Ctrl_Runnable_Init
        data-send-points:
          4 x access:
            OUT_gWND_u8FLPositionSts_Val: accessed-variable=gWND_u8FLPositionSts.Val
            OUT_gWND_u8FRPositionSts_Val: accessed-variable=gWND_u8FRPositionSts.Val
            OUT_gWND_u8RLPositionSts_Val: accessed-variable=gWND_u8RLPositionSts.Val
            OUT_gWND_u8RRPositionSts_Val: accessed-variable=gWND_u8RRPositionSts.Val
      runnable Win_Ctrl_Runnable_10ms
        data-receive-point-by-arguments:
          129 x access:
            IN_gASI_bCCULostCommon_Val: accessed-variable=gASI_bCCULostCommon.Val
            IN_gASI_bFLDoorHSUSw_Val: accessed-variable=gASI_bFLDoorHSUSw.Val
            IN_gASI_bFRDoorHSUSw_Val: accessed-variable=gASI_bFRDoorHSUSw.Val
            IN_gASI_bPowerOnReset_Val: accessed-variable=gASI_bPowerOnReset.Val
            IN_gASI_bRLDoorHSUSw_Val: accessed-variable=gASI_bRLDoorHSUSw.Val
            IN_gASI_bRRDoorHSUSw_Val: accessed-variable=gASI_bRRDoorHSUSw.Val
            IN_gASI_bWindowdInhibitSw_Val: accessed-variable=gASI_bWindowdInhibitSw.Val
            IN_gASI_u8FLWindowSw_Val: accessed-variable=gASI_u8FLWindowSw.Val
            IN_gASI_u8FRLocalWindowSw_Val: accessed-variable=gASI_u8FRLocalWindowSw.Val
            IN_gASI_u8FRWindowSw_Val: accessed-variable=gASI_u8FRWindowSw.Val
            IN_gASI_u8RLLocalWindowSw_Val: accessed-variable=gASI_u8RLLocalWindowSw.Val
            IN_gASI_u8RLWindowSw_Val: accessed-variable=gASI_u8RLWindowSw.Val
            IN_gASI_u8RRLocalWindowSw_Val: accessed-variable=gASI_u8RRLocalWindowSw.Val
            IN_gASI_u8RRWindowSw_Val: accessed-variable=gASI_u8RRWindowSw.Val
            IN_gCAN_bPWL_FLWinRelearnReq_Val: accessed-variable=gCAN_bPWL_FLWinRelearnReq.Val
            IN_gCAN_bPWL_FRWinRelearnReq_Val: accessed-variable=gCAN_bPWL_FRWinRelearnReq.Val
            IN_gCAN_bPWL_RLWinRelearnReq_Val: accessed-variable=gCAN_bPWL_RLWinRelearnReq.Val
            IN_gCAN_bPWL_RRWinRelearnReq_Val: accessed-variable=gCAN_bPWL_RRWinRelearnReq.Val
            IN_gCAN_u8POD_FLWinShortDropCmd_Val: accessed-variable=gCAN_u8POD_FLWinShortDropCmd.Val
            IN_gCAN_u8POD_FRWinShortDropCmd_Val: accessed-variable=gCAN_u8POD_FRWinShortDropCmd.Val
            IN_gCAN_u8POD_RLWinShortDropCmd_Val: accessed-variable=gCAN_u8POD_RLWinShortDropCmd.Val
            IN_gCAN_u8POD_RRWinShortDropCmd_Val: accessed-variable=gCAN_u8POD_RRWinShortDropCmd.Val
            IN_gCAN_u8PWL_FLWinMotorOpeCtr_Val: accessed-variable=gCAN_u8PWL_FLWinMotorOpeCtr.Val
            IN_gCAN_u8PWL_FLWinMotorTargetPstCtr_Val: accessed-variable=gCAN_u8PWL_FLWinMotorTargetPstCtr.Val
            IN_gCAN_u8PWL_FRWinMotorOpeCtr_Val: accessed-variable=gCAN_u8PWL_FRWinMotorOpeCtr.Val
            IN_gCAN_u8PWL_FRWinMotorTargetPstCtr_Val: accessed-variable=gCAN_u8PWL_FRWinMotorTargetPstCtr.Val
            IN_gCAN_u8PWL_RLWinMotorOpeCtr_Val: accessed-variable=gCAN_u8PWL_RLWinMotorOpeCtr.Val
            IN_gCAN_u8PWL_RLWinMotorTargetPstCtr_Val: accessed-variable=gCAN_u8PWL_RLWinMotorTargetPstCtr.Val
            IN_gCAN_u8PWL_RRWinMotorOpeCtr_Val: accessed-variable=gCAN_u8PWL_RRWinMotorOpeCtr.Val
            IN_gCAN_u8PWL_RRWinMotorTargetPstCtr_Val: accessed-variable=gCAN_u8PWL_RRWinMotorTargetPstCtr.Val
            IN_gCAN_u8UMM_UsageModeSt_Val: accessed-variable=gCAN_u8UMM_UsageModeSt.Val
            IN_gCFG_bFLDoorFramelessGlassCfg_Val: accessed-variable=gCFG_bFLDoorFramelessGlassCfg.Val
            IN_gCFG_bFRDoorFramelessGlassCfg_Val: accessed-variable=gCFG_bFRDoorFramelessGlassCfg.Val
            IN_gCFG_bRLDoorFramelessGlassCfg_Val: accessed-variable=gCFG_bRLDoorFramelessGlassCfg.Val
            IN_gCFG_bRRDoorFramelessGlassCfg_Val: accessed-variable=gCFG_bRRDoorFramelessGlassCfg.Val
            IN_gCFG_u8DriverSideWinSwType_Val: accessed-variable=gCFG_u8DriverSideWinSwType.Val
            IN_gCFG_u8LocalSideWinSwType_Val: accessed-variable=gCFG_u8LocalSideWinSwType.Val
            IN_gCFG_u8PwrRelsType_Val: accessed-variable=gCFG_u8PwrRelsType.Val
            IN_gDCU_bFLReverseFlag_Val: accessed-variable=gDCU_bFLReverseFlag.Val
            IN_gDCU_bFLWinDownOutput_Val: accessed-variable=gDCU_bFLWinDownOutput.Val
            IN_gDCU_bFLWinUpOutput_Val: accessed-variable=gDCU_bFLWinUpOutput.Val
            IN_gDCU_bFRReverseFlag_Val: accessed-variable=gDCU_bFRReverseFlag.Val
            IN_gDCU_bFRWinDownOutput_Val: accessed-variable=gDCU_bFRWinDownOutput.Val
            IN_gDCU_bFRWinUpOutput_Val: accessed-variable=gDCU_bFRWinUpOutput.Val
            IN_gDCU_bRLReverseFlag_Val: accessed-variable=gDCU_bRLReverseFlag.Val
            IN_gDCU_bRLWinDownOutput_Val: accessed-variable=gDCU_bRLWinDownOutput.Val
            IN_gDCU_bRLWinUpOutput_Val: accessed-variable=gDCU_bRLWinUpOutput.Val
            IN_gDCU_bRRReverseFlag_Val: accessed-variable=gDCU_bRRReverseFlag.Val
            IN_gDCU_bRRWinDownOutput_Val: accessed-variable=gDCU_bRRWinDownOutput.Val
            IN_gDCU_bRRWinUpOutput_Val: accessed-variable=gDCU_bRRWinUpOutput.Val
            IN_gDoor_bFLDoorAjarSt_Val: accessed-variable=gDoor_bFLDoorAjarSt.Val
            IN_gDoor_bFRDoorAjarSt_Val: accessed-variable=gDoor_bFRDoorAjarSt.Val
            IN_gDoor_bRLDoorAjarSt_Val: accessed-variable=gDoor_bRLDoorAjarSt.Val
            IN_gDoor_bRRDoorAjarSt_Val: accessed-variable=gDoor_bRRDoorAjarSt.Val
            IN_gLock_bFLDoorLockFbSt_Val: accessed-variable=gLock_bFLDoorLockFbSt.Val
            IN_gLock_bFRDoorLockFbSt_Val: accessed-variable=gLock_bFRDoorLockFbSt.Val
            IN_gLock_bRLDoorLockFbSt_Val: accessed-variable=gLock_bRLDoorLockFbSt.Val
            IN_gLock_bRRDoorLockFbSt_Val: accessed-variable=gLock_bRRDoorLockFbSt.Val
            IN_gPRM_bPODRelsCinchFunEnCfgFL_Val: accessed-variable=gPRM_bPODRelsCinchFunEnCfgFL.Val
            IN_gPRM_bPODRelsCinchFunEnCfgFR_Val: accessed-variable=gPRM_bPODRelsCinchFunEnCfgFR.Val
            IN_gPRM_bPODRelsCinchFunEnCfgRL_Val: accessed-variable=gPRM_bPODRelsCinchFunEnCfgRL.Val
            IN_gPRM_bPODRelsCinchFunEnCfgRR_Val: accessed-variable=gPRM_bPODRelsCinchFunEnCfgRR.Val
            IN_gPRM_u8FLPowerDoorReqWinOpenPst_Val: accessed-variable=gPRM_u8FLPowerDoorReqWinOpenPst.Val
            IN_gPRM_u8FLWinShortDropPst_Val: accessed-variable=gPRM_u8FLWinShortDropPst.Val
            IN_gPRM_u8FRPowerDoorReqWinOpenPst_Val: accessed-variable=gPRM_u8FRPowerDoorReqWinOpenPst.Val
            IN_gPRM_u8FRWinShortDropPst_Val: accessed-variable=gPRM_u8FRWinShortDropPst.Val
            IN_gPRM_u8RLPowerDoorReqWinOpenPst_Val: accessed-variable=gPRM_u8RLPowerDoorReqWinOpenPst.Val
            IN_gPRM_u8RLWinShortDropPst_Val: accessed-variable=gPRM_u8RLWinShortDropPst.Val
            IN_gPRM_u8RRPowerDoorReqWinOpenPst_Val: accessed-variable=gPRM_u8RRPowerDoorReqWinOpenPst.Val
            IN_gPRM_u8RRWinShortDropPst_Val: accessed-variable=gPRM_u8RRWinShortDropPst.Val
            IN_gPRM_u8UINM_DriverSideWinSwActivetime_Val: accessed-variable=gPRM_u8UINM_DriverSideWinSwActivetime.Val
            IN_gPRM_u8UINM_LocalSideWinSwActivetime_Val: accessed-variable=gPRM_u8UINM_LocalSideWinSwActivetime.Val
            IN_gPRM_u8WndLckLEDPWM_Lv1_Val: accessed-variable=gPRM_u8WndLckLEDPWM_Lv1.Val
            IN_gPRM_u8WndLckLEDPWM_Lv2_Val: accessed-variable=gPRM_u8WndLckLEDPWM_Lv2.Val
            IN_gPRM_u8WndVentilationPst_Val: accessed-variable=gPRM_u8WndVentilationPst.Val
            IN_gSLC_bFLAPHappen_Val: accessed-variable=gSLC_bFLAPHappen.Val
            IN_gSLC_bFLActiveFlg_Val: accessed-variable=gSLC_bFLActiveFlg.Val
            IN_gSLC_bFLBDCSStopReq_Val: accessed-variable=gSLC_bFLBDCSStopReq.Val
            IN_gSLC_bFLIsInAPRange_Val: accessed-variable=gSLC_bFLIsInAPRange.Val
            IN_gSLC_bFLPositionLostFlg_Val: accessed-variable=gSLC_bFLPositionLostFlg.Val
            IN_gSLC_bFLTDCSStopReq_Val: accessed-variable=gSLC_bFLTDCSStopReq.Val
            IN_gSLC_bFRAPHappen_Val: accessed-variable=gSLC_bFRAPHappen.Val
            IN_gSLC_bFRActiveFlg_Val: accessed-variable=gSLC_bFRActiveFlg.Val
            IN_gSLC_bFRBDCSStopReq_Val: accessed-variable=gSLC_bFRBDCSStopReq.Val
            IN_gSLC_bFRIsInAPRange_Val: accessed-variable=gSLC_bFRIsInAPRange.Val
            IN_gSLC_bFRPositionLostFlg_Val: accessed-variable=gSLC_bFRPositionLostFlg.Val
            IN_gSLC_bFRTDCSStopReq_Val: accessed-variable=gSLC_bFRTDCSStopReq.Val
            IN_gSLC_bRLAPHappen_Val: accessed-variable=gSLC_bRLAPHappen.Val
            IN_gSLC_bRLActiveFlg_Val: accessed-variable=gSLC_bRLActiveFlg.Val
            IN_gSLC_bRLBDCSStopReq_Val: accessed-variable=gSLC_bRLBDCSStopReq.Val
            IN_gSLC_bRLIsInAPRange_Val: accessed-variable=gSLC_bRLIsInAPRange.Val
            IN_gSLC_bRLPositionLostFlg_Val: accessed-variable=gSLC_bRLPositionLostFlg.Val
            IN_gSLC_bRLTDCSStopReq_Val: accessed-variable=gSLC_bRLTDCSStopReq.Val
            IN_gSLC_bRRAPHappen_Val: accessed-variable=gSLC_bRRAPHappen.Val
            IN_gSLC_bRRActiveFlg_Val: accessed-variable=gSLC_bRRActiveFlg.Val
            IN_gSLC_bRRBDCSStopReq_Val: accessed-variable=gSLC_bRRBDCSStopReq.Val
            IN_gSLC_bRRIsInAPRange_Val: accessed-variable=gSLC_bRRIsInAPRange.Val
            IN_gSLC_bRRPositionLostFlg_Val: accessed-variable=gSLC_bRRPositionLostFlg.Val
            IN_gSLC_bRRTDCSStopReq_Val: accessed-variable=gSLC_bRRTDCSStopReq.Val
            IN_gSLC_u16FLActualCurrent_Val: accessed-variable=gSLC_u16FLActualCurrent.Val
            IN_gSLC_u16FLRpPosition_Val: accessed-variable=gSLC_u16FLRpPosition.Val
            IN_gSLC_u16FLRpTravelLength_Val: accessed-variable=gSLC_u16FLRpTravelLength.Val
            IN_gSLC_u16FRActualCurrent_Val: accessed-variable=gSLC_u16FRActualCurrent.Val
            IN_gSLC_u16FRRpPosition_Val: accessed-variable=gSLC_u16FRRpPosition.Val
            IN_gSLC_u16FRRpTravelLength_Val: accessed-variable=gSLC_u16FRRpTravelLength.Val
            IN_gSLC_u16RLActualCurrent_Val: accessed-variable=gSLC_u16RLActualCurrent.Val
            IN_gSLC_u16RLRpPosition_Val: accessed-variable=gSLC_u16RLRpPosition.Val
            IN_gSLC_u16RLRpTravelLength_Val: accessed-variable=gSLC_u16RLRpTravelLength.Val
            IN_gSLC_u16RRActualCurrent_Val: accessed-variable=gSLC_u16RRActualCurrent.Val
            IN_gSLC_u16RRRpPosition_Val: accessed-variable=gSLC_u16RRRpPosition.Val
            IN_gSLC_u16RRRpTravelLength_Val: accessed-variable=gSLC_u16RRRpTravelLength.Val
            IN_gSLC_u16VbatVoltage_Val: accessed-variable=gSLC_u16VbatVoltage.Val
            IN_gSLC_u8FLCurrtFixFlg_Val: accessed-variable=gSLC_u8FLCurrtFixFlg.Val
            IN_gSLC_u8FLCurrtOverFlg_Val: accessed-variable=gSLC_u8FLCurrtOverFlg.Val
            IN_gSLC_u8FLNormalizeSts_Val: accessed-variable=gSLC_u8FLNormalizeSts.Val
            IN_gSLC_u8FRCurrtFixFlg_Val: accessed-variable=gSLC_u8FRCurrtFixFlg.Val
            IN_gSLC_u8FRCurrtOverFlg_Val: accessed-variable=gSLC_u8FRCurrtOverFlg.Val
            IN_gSLC_u8FRNormalizeSts_Val: accessed-variable=gSLC_u8FRNormalizeSts.Val
            IN_gSLC_u8RLCurrtFixFlg_Val: accessed-variable=gSLC_u8RLCurrtFixFlg.Val
            IN_gSLC_u8RLCurrtOverFlg_Val: accessed-variable=gSLC_u8RLCurrtOverFlg.Val
            IN_gSLC_u8RLNormalizeSts_Val: accessed-variable=gSLC_u8RLNormalizeSts.Val
            IN_gSLC_u8RRCurrtFixFlg_Val: accessed-variable=gSLC_u8RRCurrtFixFlg.Val
            IN_gSLC_u8RRCurrtOverFlg_Val: accessed-variable=gSLC_u8RRCurrtOverFlg.Val
            IN_gSLC_u8RRNormalizeSts_Val: accessed-variable=gSLC_u8RRNormalizeSts.Val
            IN_gVRM_u16BatteryVolt_mv_Val: accessed-variable=gVRM_u16BatteryVolt_mv.Val
            IN_gWND_u8DrvWinOutput_Val: accessed-variable=gWND_u8DrvWinOutput.Val
            IN_gWND_u8PsgWinOutput_Val: accessed-variable=gWND_u8PsgWinOutput.Val
            IN_gWND_u8RLWinOutput_Val: accessed-variable=gWND_u8RLWinOutput.Val
            IN_gWND_u8RRWinOutput_Val: accessed-variable=gWND_u8RRWinOutput.Val
        data-send-points:
          83 x access:
            OUT_gWND_u8DrvSideFLWinSwSt_Val: accessed-variable=gWND_u8DrvSideFLWinSwSt.Val
            OUT_gWND_u8DrvSideFRWinSwSt_Val: accessed-variable=gWND_u8DrvSideFRWinSwSt.Val
            OUT_gWND_u8DrvSideRLWinSwSt_Val: accessed-variable=gWND_u8DrvSideRLWinSwSt.Val
            OUT_gWND_u8DrvSideRRWinSwSt_Val: accessed-variable=gWND_u8DrvSideRRWinSwSt.Val
            OUT_gWND_u8LocalSideFRWinSwSt_Val: accessed-variable=gWND_u8LocalSideFRWinSwSt.Val
            OUT_gWND_u8LocalSideRLWinSwSt_Val: accessed-variable=gWND_u8LocalSideRLWinSwSt.Val
            OUT_gWND_u8LocalSideRRWinSwSt_Val: accessed-variable=gWND_u8LocalSideRRWinSwSt.Val
            OUT_gWND_u8CurrentFLWinPst_Val: accessed-variable=gWND_u8CurrentFLWinPst.Val
            OUT_gWND_u8CurrentFRWinPst_Val: accessed-variable=gWND_u8CurrentFRWinPst.Val
            OUT_gWND_u8CurrentRLWinPst_Val: accessed-variable=gWND_u8CurrentRLWinPst.Val
            OUT_gWND_u8CurrentRRWinPst_Val: accessed-variable=gWND_u8CurrentRRWinPst.Val
            OUT_gWin_u8FLOutputSts_Val: accessed-variable=gWin_u8FLOutputSts.Val
            OUT_gWin_u8FROutputSts_Val: accessed-variable=gWin_u8FROutputSts.Val
            OUT_gWin_u8RLOutputSts_Val: accessed-variable=gWin_u8RLOutputSts.Val
            OUT_gWin_u8RROutputSts_Val: accessed-variable=gWin_u8RROutputSts.Val
            OUT_gWND_bFLWinMotErrSt_Val: accessed-variable=gWND_bFLWinMotErrSt.Val
            OUT_gWND_bFRWinMotErrSt_Val: accessed-variable=gWND_bFRWinMotErrSt.Val
            OUT_gWND_bRLWinMotErrSt_Val: accessed-variable=gWND_bRLWinMotErrSt.Val
            OUT_gWND_bRRWinMotErrSt_Val: accessed-variable=gWND_bRRWinMotErrSt.Val
            OUT_gWND_u32AllowSleep_Local_Val: accessed-variable=gWND_u32AllowSleep_Local.Val
            OUT_gWND_u8Wakeup_Val: accessed-variable=gWND_u8Wakeup.Val
            OUT_gWND_u32AllowSleep_NW_Val: accessed-variable=gWND_u32AllowSleep_NW.Val
            OUT_gWND_bFLNormStartFlg_Val: accessed-variable=gWND_bFLNormStartFlg.Val
            OUT_gWND_bFRNormStartFlg_Val: accessed-variable=gWND_bFRNormStartFlg.Val
            OUT_gWND_bRLNormStartFlg_Val: accessed-variable=gWND_bRLNormStartFlg.Val
            OUT_gWND_bRRNormStartFlg_Val: accessed-variable=gWND_bRRNormStartFlg.Val
            OUT_gWND_bRLDoorOutsideSwSt_Val: accessed-variable=gWND_bRLDoorOutsideSwSt.Val
            OUT_gWND_bRRDoorOutsideSwSt_Val: accessed-variable=gWND_bRRDoorOutsideSwSt.Val
            OUT_gWND_bFRDoorOutsideSwSt_Val: accessed-variable=gWND_bFRDoorOutsideSwSt.Val
            OUT_gWND_bFLDoorOutsideSwSt_Val: accessed-variable=gWND_bFLDoorOutsideSwSt.Val
            OUT_gWin_bRLWinShortDropSt_Val: accessed-variable=gWin_bRLWinShortDropSt.Val
            OUT_gWin_bRRWinShortDropSt_Val: accessed-variable=gWin_bRRWinShortDropSt.Val
            OUT_gWin_bFRWinShortDropSt_Val: accessed-variable=gWin_bFRWinShortDropSt.Val
            OUT_gWin_bFLWinShortDropSt_Val: accessed-variable=gWin_bFLWinShortDropSt.Val
            OUT_gWin_bRLOutSideDoorSwFlg_Val: accessed-variable=gWin_bRLOutSideDoorSwFlg.Val
            OUT_gWin_bRROutSideDoorSwFlg_Val: accessed-variable=gWin_bRROutSideDoorSwFlg.Val
            OUT_gWND_bFLUpOutputWinSt_Val: accessed-variable=gWND_bFLUpOutputWinSt.Val
            OUT_gWND_bFRUpOutputWinSt_Val: accessed-variable=gWND_bFRUpOutputWinSt.Val
            OUT_gWND_bRLUpOutputWinSt_Val: accessed-variable=gWND_bRLUpOutputWinSt.Val
            OUT_gWND_bRRUpOutputWinSt_Val: accessed-variable=gWND_bRRUpOutputWinSt.Val
            OUT_gWND_bFLDnOutputWinSt_Val: accessed-variable=gWND_bFLDnOutputWinSt.Val
            OUT_gWND_bFRDnOutputWinSt_Val: accessed-variable=gWND_bFRDnOutputWinSt.Val
            OUT_gWND_bRLDnOutputWinSt_Val: accessed-variable=gWND_bRLDnOutputWinSt.Val
            OUT_gWND_bRRDnOutputWinSt_Val: accessed-variable=gWND_bRRDnOutputWinSt.Val
            OUT_gWND_u8FLPositionSts_Val: accessed-variable=gWND_u8FLPositionSts.Val
            OUT_gWND_u8FRPositionSts_Val: accessed-variable=gWND_u8FRPositionSts.Val
            OUT_gWND_u8RLPositionSts_Val: accessed-variable=gWND_u8RLPositionSts.Val
            OUT_gWND_u8RRPositionSts_Val: accessed-variable=gWND_u8RRPositionSts.Val
            OUT_gWin_bFLOutSideDoorSwFlg_Val: accessed-variable=gWin_bFLOutSideDoorSwFlg.Val
            OUT_gWin_bFROutSideDoorSwFlg_Val: accessed-variable=gWin_bFROutSideDoorSwFlg.Val
            OUT_gWin_u8FLWNDExecReq_Val: accessed-variable=gWin_u8FLWNDExecReq.Val
            OUT_gWin_u8FRWNDExecReq_Val: accessed-variable=gWin_u8FRWNDExecReq.Val
            OUT_gWin_u8RLWNDExecReq_Val: accessed-variable=gWin_u8RLWNDExecReq.Val
            OUT_gWin_u8RRWNDExecReq_Val: accessed-variable=gWin_u8RRWNDExecReq.Val
            OUT_gWin_bAllow_FLSPsleep_Val: accessed-variable=gWin_bAllow_FLSPsleep.Val
            OUT_gWin_bAllow_FRSPsleep_Val: accessed-variable=gWin_bAllow_FRSPsleep.Val
            OUT_gWin_bAllow_RLSPsleep_Val: accessed-variable=gWin_bAllow_RLSPsleep.Val
            OUT_gWin_bAllow_RRSPsleep_Val: accessed-variable=gWin_bAllow_RRSPsleep.Val
            OUT_gWin_bSpecialFlag_FL_Val: accessed-variable=gWin_bSpecialFlag_FL.Val
            OUT_gWin_bSpecialFlag_FR_Val: accessed-variable=gWin_bSpecialFlag_FR.Val
            OUT_gWin_bSpecialFlag_RL_Val: accessed-variable=gWin_bSpecialFlag_RL.Val
            OUT_gWin_bSpecialFlag_RR_Val: accessed-variable=gWin_bSpecialFlag_RR.Val
            OUT_gWin_u8FLWNDCmd_Val: accessed-variable=gWin_u8FLWNDCmd.Val
            OUT_gWin_u8FRWNDCmd_Val: accessed-variable=gWin_u8FRWNDCmd.Val
            OUT_gWin_u8RLWNDCmd_Val: accessed-variable=gWin_u8RLWNDCmd.Val
            OUT_gWin_u8RRWNDCmd_Val: accessed-variable=gWin_u8RRWNDCmd.Val
            OUT_gWin_u8FLWNDCmdSrc_Val: accessed-variable=gWin_u8FLWNDCmdSrc.Val
            OUT_gWin_u8FRWNDCmdSrc_Val: accessed-variable=gWin_u8FRWNDCmdSrc.Val
            OUT_gWin_u8RLWNDCmdSrc_Val: accessed-variable=gWin_u8RLWNDCmdSrc.Val
            OUT_gWin_u8RRWNDCmdSrc_Val: accessed-variable=gWin_u8RRWNDCmdSrc.Val
            OUT_gWin_bFLWinShrtDrpFlg_Val: accessed-variable=gWin_bFLWinShrtDrpFlg.Val
            OUT_gWin_bFRWinShrtDrpFlg_Val: accessed-variable=gWin_bFRWinShrtDrpFlg.Val
            OUT_gWin_bRLWinShrtDrpFlg_Val: accessed-variable=gWin_bRLWinShrtDrpFlg.Val
            OUT_gWin_bRRWinShrtDrpFlg_Val: accessed-variable=gWin_bRRWinShrtDrpFlg.Val
            OUT_gWND_bPsgWinLockBtnSt_Val: accessed-variable=gWND_bPsgWinLockBtnSt.Val
            OUT_gWin_u8PWL_WinOpeationSt_FLWinSt_Val: accessed-variable=gWin_u8PWL_WinOpeationSt_FLWinSt.Val
            OUT_gWin_u8PWL_WinOpeationSt_FRWinSt_Val: accessed-variable=gWin_u8PWL_WinOpeationSt_FRWinSt.Val
            OUT_gWin_u8PWL_WinOpeationSt_RLWinSt_Val: accessed-variable=gWin_u8PWL_WinOpeationSt_RLWinSt.Val
            OUT_gWin_u8PWL_WinOpeationSt_RRWinSt_Val: accessed-variable=gWin_u8PWL_WinOpeationSt_RRWinSt.Val
            OUT_gWin_bFLDelayAdjSpdFlg_Val: accessed-variable=gWin_bFLDelayAdjSpdFlg.Val
            OUT_gWin_bFRDelayAdjSpdFlg_Val: accessed-variable=gWin_bFRDelayAdjSpdFlg.Val
            OUT_gWin_bRLDelayAdjSpdFlg_Val: accessed-variable=gWin_bRLDelayAdjSpdFlg.Val
            OUT_gWin_bRRDelayAdjSpdFlg_Val: accessed-variable=gWin_bRRDelayAdjSpdFlg.Val
package /UAES/ASW/PortInterfaces
  219 x sender receiver interface:
    gCAN_u8PWL_FLWinMotorTargetPstCtr
      data Val: category=VALUE, sw-calibration-access=READ-ONLY, type=uint8
    gCAN_u8PWL_FRWinMotorTargetPstCtr
      data Val: category=VALUE, sw-calibration-access=READ-ONLY, type=uint8
    gCAN_u8PWL_RLWinMotorTargetPstCtr
      data Val: category=VALUE, sw-calibration-access=READ-ONLY, type=uint8
    gCAN_u8PWL_RRWinMotorTargetPstCtr
      data Val: category=VALUE, sw-calibration-access=READ-ONLY, type=uint8
    gCAN_u8PWL_FLWinMotorOpeCtr
      data Val: category=VALUE, sw-calibration-access=READ-ONLY, type=uint8
    gCAN_u8PWL_FRWinMotorOpeCtr
      data Val: category=VALUE, sw-calibration-access=READ-ONLY, type=uint8
    gCAN_u8PWL_RLWinMotorOpeCtr
      data Val: category=VALUE, sw-calibration-access=READ-ONLY, type=uint8
    gCAN_u8PWL_RRWinMotorOpeCtr
      data Val: category=VALUE, sw-calibration-access=READ-ONLY, type=uint8
    gCAN_u8UMM_UsageModeSt
      data Val: category=VALUE, sw-calibration-access=READ-ONLY, type=uint8
    gASI_u8FLWindowSw
      data Val: category=VALUE, sw-calibration-access=READ-ONLY, type=uint8
    gASI_u8FRWindowSw
      data Val: category=VALUE, sw-calibration-access=READ-ONLY, type=uint8
    gASI_u8RLWindowSw
      data Val: category=VALUE, sw-calibration-access=READ-ONLY, type=uint8
    gASI_u8RRWindowSw
      data Val: category=VALUE, sw-calibration-access=READ-ONLY, type=uint8
    gASI_u8FRLocalWindowSw
      data Val: category=VALUE, sw-calibration-access=READ-ONLY, type=uint8
    gASI_u8RLLocalWindowSw
      data Val: category=VALUE, sw-calibration-access=READ-ONLY, type=uint8
    gASI_u8RRLocalWindowSw
      data Val: category=VALUE, sw-calibration-access=READ-ONLY, type=uint8
    gASI_bWindowdInhibitSw
      data Val: category=VALUE, sw-calibration-access=READ-ONLY, type=boolean
    gASI_u8RLBossWindowSw
      data Val: category=VALUE, sw-calibration-access=READ-ONLY, type=uint8
    gASI_u8RRBossWindowSw
      data Val: category=VALUE, sw-calibration-access=READ-ONLY, type=uint8
    gSLC_u16FLActualCurrent
      data Val: category=VALUE, sw-calibration-access=READ-ONLY, type=uint16
    gSLC_u16FRActualCurrent
      data Val: category=VALUE, sw-calibration-access=READ-ONLY, type=uint16
    gSLC_u16RLActualCurrent
      data Val: category=VALUE, sw-calibration-access=READ-ONLY, type=uint16
    gSLC_u16RRActualCurrent
      data Val: category=VALUE, sw-calibration-access=READ-ONLY, type=uint16
    gSLC_u16FLRpTravelLength
      data Val: category=VALUE, sw-calibration-access=READ-ONLY, type=uint16
    gSLC_u16FRRpTravelLength
      data Val: category=VALUE, sw-calibration-access=READ-ONLY, type=uint16
    gSLC_u16RLRpTravelLength
      data Val: category=VALUE, sw-calibration-access=READ-ONLY, type=uint16
    gSLC_u16RRRpTravelLength
      data Val: category=VALUE, sw-calibration-access=READ-ONLY, type=uint16
    gSLC_u16FLRpPosition
      data Val: category=VALUE, sw-calibration-access=READ-ONLY, type=uint16
    gSLC_u16FRRpPosition
      data Val: category=VALUE, sw-calibration-access=READ-ONLY, type=uint16
    gSLC_u16RLRpPosition
      data Val: category=VALUE, sw-calibration-access=READ-ONLY, type=uint16
    gSLC_u16RRRpPosition
      data Val: category=VALUE, sw-calibration-access=READ-ONLY, type=uint16
    gSLC_u8FLCurrtOverFlg
      data Val: category=VALUE, sw-calibration-access=READ-ONLY, type=uint8
    gSLC_u8FRCurrtOverFlg
      data Val: category=VALUE, sw-calibration-access=READ-ONLY, type=uint8
    gSLC_u8RLCurrtOverFlg
      data Val: category=VALUE, sw-calibration-access=READ-ONLY, type=uint8
    gSLC_u8RRCurrtOverFlg
      data Val: category=VALUE, sw-calibration-access=READ-ONLY, type=uint8
    gSLC_u16VbatVoltage
      data Val: category=VALUE, sw-calibration-access=READ-ONLY, type=uint16
    gSLC_u8FLCurrtFixFlg
      data Val: category=VALUE, sw-calibration-access=READ-ONLY, type=uint8
    gSLC_u8FRCurrtFixFlg
      data Val: category=VALUE, sw-calibration-access=READ-ONLY, type=uint8
    gSLC_u8RLCurrtFixFlg
      data Val: category=VALUE, sw-calibration-access=READ-ONLY, type=uint8
    gSLC_u8RRCurrtFixFlg
      data Val: category=VALUE, sw-calibration-access=READ-ONLY, type=uint8
    gSLC_u8FLNormalizeSts
      data Val: category=VALUE, sw-calibration-access=READ-ONLY, type=uint8
    gSLC_u8FRNormalizeSts
      data Val: category=VALUE, sw-calibration-access=READ-ONLY, type=uint8
    gSLC_u8RLNormalizeSts
      data Val: category=VALUE, sw-calibration-access=READ-ONLY, type=uint8
    gSLC_u8RRNormalizeSts
      data Val: category=VALUE, sw-calibration-access=READ-ONLY, type=uint8
    gSLC_bFLAPHappen
      data Val: category=VALUE, sw-calibration-access=READ-ONLY, type=boolean
    gSLC_bFRAPHappen
      data Val: category=VALUE, sw-calibration-access=READ-ONLY, type=boolean
    gSLC_bRLAPHappen
      data Val: category=VALUE, sw-calibration-access=READ-ONLY, type=boolean
    gSLC_bRRAPHappen
      data Val: category=VALUE, sw-calibration-access=READ-ONLY, type=boolean
    gSLC_bFLTDCSStopReq
      data Val: category=VALUE, sw-calibration-access=READ-ONLY, type=boolean
    gSLC_bFRTDCSStopReq
      data Val: category=VALUE, sw-calibration-access=READ-ONLY, type=boolean
    gSLC_bRLTDCSStopReq
      data Val: category=VALUE, sw-calibration-access=READ-ONLY, type=boolean
    gSLC_bRRTDCSStopReq
      data Val: category=VALUE, sw-calibration-access=READ-ONLY, type=boolean
    gSLC_bFLBDCSStopReq
      data Val: category=VALUE, sw-calibration-access=READ-ONLY, type=boolean
    gSLC_bFRBDCSStopReq
      data Val: category=VALUE, sw-calibration-access=READ-ONLY, type=boolean
    gSLC_bRLBDCSStopReq
      data Val: category=VALUE, sw-calibration-access=READ-ONLY, type=boolean
    gSLC_bRRBDCSStopReq
      data Val: category=VALUE, sw-calibration-access=READ-ONLY, type=boolean
    gSLC_bFLIsInAPRange
      data Val: category=VALUE, sw-calibration-access=READ-ONLY, type=boolean
    gSLC_bFRIsInAPRange
      data Val: category=VALUE, sw-calibration-access=READ-ONLY, type=boolean
    gSLC_bRLIsInAPRange
      data Val: category=VALUE, sw-calibration-access=READ-ONLY, type=boolean
    gSLC_bRRIsInAPRange
      data Val: category=VALUE, sw-calibration-access=READ-ONLY, type=boolean
    gSLC_bFLPositionLostFlg
      data Val: category=VALUE, sw-calibration-access=READ-ONLY, type=boolean
    gSLC_bFRPositionLostFlg
      data Val: category=VALUE, sw-calibration-access=READ-ONLY, type=boolean
    gSLC_bRLPositionLostFlg
      data Val: category=VALUE, sw-calibration-access=READ-ONLY, type=boolean
    gSLC_bRRPositionLostFlg
      data Val: category=VALUE, sw-calibration-access=READ-ONLY, type=boolean
    gDoor_bFLDoorAjarSt
      data Val: category=VALUE, sw-calibration-access=READ-ONLY, type=boolean
    gDoor_bFRDoorAjarSt
      data Val: category=VALUE, sw-calibration-access=READ-ONLY, type=boolean
    gDoor_bRLDoorAjarSt
      data Val: category=VALUE, sw-calibration-access=READ-ONLY, type=boolean
    gDoor_bRRDoorAjarSt
      data Val: category=VALUE, sw-calibration-access=READ-ONLY, type=boolean
    gASI_bRLDoorHSUSw
      data Val: category=VALUE, sw-calibration-access=READ-ONLY, type=boolean
    gASI_bRRDoorHSUSw
      data Val: category=VALUE, sw-calibration-access=READ-ONLY, type=boolean
    gASI_bFLDoorHSUSw
      data Val: category=VALUE, sw-calibration-access=READ-ONLY, type=boolean
    gASI_bFRDoorHSUSw
      data Val: category=VALUE, sw-calibration-access=READ-ONLY, type=boolean
    gLock_bRLDoorLockFbSt
      data Val: category=VALUE, sw-calibration-access=READ-ONLY, type=boolean
    gLock_bRRDoorLockFbSt
      data Val: category=VALUE, sw-calibration-access=READ-ONLY, type=boolean
    gLock_bFLDoorLockFbSt
      data Val: category=VALUE, sw-calibration-access=READ-ONLY, type=boolean
    gLock_bFRDoorLockFbSt
      data Val: category=VALUE, sw-calibration-access=READ-ONLY, type=boolean
    gCFG_bFLDoorFramelessGlassCfg
      data Val: category=VALUE, sw-calibration-access=READ-ONLY, type=boolean
    gCFG_bFRDoorFramelessGlassCfg
      data Val: category=VALUE, sw-calibration-access=READ-ONLY, type=boolean
    gCFG_bRLDoorFramelessGlassCfg
      data Val: category=VALUE, sw-calibration-access=READ-ONLY, type=boolean
    gCFG_bRRDoorFramelessGlassCfg
      data Val: category=VALUE, sw-calibration-access=READ-ONLY, type=boolean
    gCAN_u8POD_FLWinShortDropCmd
      data Val: category=VALUE, sw-calibration-access=READ-ONLY, type=uint8
    gCAN_u8POD_FRWinShortDropCmd
      data Val: category=VALUE, sw-calibration-access=READ-ONLY, type=uint8
    gCAN_u8POD_RLWinShortDropCmd
      data Val: category=VALUE, sw-calibration-access=READ-ONLY, type=uint8
    gCAN_u8POD_RRWinShortDropCmd
      data Val: category=VALUE, sw-calibration-access=READ-ONLY, type=uint8
    gCFG_u8PwrRelsType
      data Val: category=VALUE, sw-calibration-access=READ-ONLY, type=uint8
    gCFG_bWndVentilationFunCfg
      data Val: category=VALUE, sw-calibration-access=READ-ONLY, type=boolean
    gPRM_u8WndVentilationPst
      data Val: category=VALUE, sw-calibration-access=READ-ONLY, type=uint8
    gPRM_u8WndLckLEDPWM_Lv1
      data Val: category=VALUE, sw-calibration-access=READ-ONLY, type=uint8
    gPRM_u8WndLckLEDPWM_Lv2
      data Val: category=VALUE, sw-calibration-access=READ-ONLY, type=uint8
    gPRM_u8FLWinShortDropPst
      data Val: category=VALUE, sw-calibration-access=READ-ONLY, type=uint8
    gPRM_u8FRWinShortDropPst
      data Val: category=VALUE, sw-calibration-access=READ-ONLY, type=uint8
    gPRM_u8RLWinShortDropPst
      data Val: category=VALUE, sw-calibration-access=READ-ONLY, type=uint8
    gPRM_u8RRWinShortDropPst
      data Val: category=VALUE, sw-calibration-access=READ-ONLY, type=uint8
    gPRM_u8FLPowerDoorReqWinOpenPst
      data Val: category=VALUE, sw-calibration-access=READ-ONLY, type=uint8
    gPRM_u8FRPowerDoorReqWinOpenPst
      data Val: category=VALUE, sw-calibration-access=READ-ONLY, type=uint8
    gPRM_u8RLPowerDoorReqWinOpenPst
      data Val: category=VALUE, sw-calibration-access=READ-ONLY, type=uint8
    gPRM_u8RRPowerDoorReqWinOpenPst
      data Val: category=VALUE, sw-calibration-access=READ-ONLY, type=uint8
    gPRM_bPODRelsCinchFunEnCfgFL
      data Val: category=VALUE, sw-calibration-access=READ-ONLY, type=boolean
    gPRM_bPODRelsCinchFunEnCfgFR
      data Val: category=VALUE, sw-calibration-access=READ-ONLY, type=boolean
    gPRM_bPODRelsCinchFunEnCfgRL
      data Val: category=VALUE, sw-calibration-access=READ-ONLY, type=boolean
    gPRM_bPODRelsCinchFunEnCfgRR
      data Val: category=VALUE, sw-calibration-access=READ-ONLY, type=boolean
    gDCU_bFLReverseFlag
      data Val: category=VALUE, sw-calibration-access=READ-ONLY, type=boolean
    gDCU_bFRReverseFlag
      data Val: category=VALUE, sw-calibration-access=READ-ONLY, type=boolean
    gDCU_bRLReverseFlag
      data Val: category=VALUE, sw-calibration-access=READ-ONLY, type=boolean
    gDCU_bRRReverseFlag
      data Val: category=VALUE, sw-calibration-access=READ-ONLY, type=boolean
    gASI_bCCULostCommon
      data Val: category=VALUE, sw-calibration-access=READ-ONLY, type=boolean
    gASI_bPowerOnReset
      data Val: category=VALUE, sw-calibration-access=READ-ONLY, type=boolean
    gVRM_u16BatteryVolt_mv
      data Val: category=VALUE, sw-calibration-access=READ-ONLY, type=uint16
    gSLC_bFLActiveFlg
      data Val: category=VALUE, sw-calibration-access=READ-ONLY, type=boolean
    gSLC_bFRActiveFlg
      data Val: category=VALUE, sw-calibration-access=READ-ONLY, type=boolean
    gSLC_bRLActiveFlg
      data Val: category=VALUE, sw-calibration-access=READ-ONLY, type=boolean
    gSLC_bRRActiveFlg
      data Val: category=VALUE, sw-calibration-access=READ-ONLY, type=boolean
    gDCU_bFLWinUpOutput
      data Val: category=VALUE, sw-calibration-access=READ-ONLY, type=boolean
    gDCU_bFLWinDownOutput
      data Val: category=VALUE, sw-calibration-access=READ-ONLY, type=boolean
    gDCU_bFRWinUpOutput
      data Val: category=VALUE, sw-calibration-access=READ-ONLY, type=boolean
    gDCU_bFRWinDownOutput
      data Val: category=VALUE, sw-calibration-access=READ-ONLY, type=boolean
    gDCU_bRLWinUpOutput
      data Val: category=VALUE, sw-calibration-access=READ-ONLY, type=boolean
    gDCU_bRLWinDownOutput
      data Val: category=VALUE, sw-calibration-access=READ-ONLY, type=boolean
    gDCU_bRRWinUpOutput
      data Val: category=VALUE, sw-calibration-access=READ-ONLY, type=boolean
    gDCU_bRRWinDownOutput
      data Val: category=VALUE, sw-calibration-access=READ-ONLY, type=boolean
    gWin_bFLSwStuckFlg
      data Val: category=VALUE, sw-calibration-access=READ-ONLY, type=boolean
    gWin_bFRSwStuckFlg
      data Val: category=VALUE, sw-calibration-access=READ-ONLY, type=boolean
    gWin_bRLSwStuckFlg
      data Val: category=VALUE, sw-calibration-access=READ-ONLY, type=boolean
    gWin_bRRSwStuckFlg
      data Val: category=VALUE, sw-calibration-access=READ-ONLY, type=boolean
    gCAN_bPWL_FLWinRelearnReq
      data Val: category=VALUE, sw-calibration-access=READ-ONLY, type=boolean
    gCAN_bPWL_FRWinRelearnReq
      data Val: category=VALUE, sw-calibration-access=READ-ONLY, type=boolean
    gCAN_bPWL_RLWinRelearnReq
      data Val: category=VALUE, sw-calibration-access=READ-ONLY, type=boolean
    gCAN_bPWL_RRWinRelearnReq
      data Val: category=VALUE, sw-calibration-access=READ-ONLY, type=boolean
    gCFG_u8LocalSideWinSwType
      data Val: category=VALUE, sw-calibration-access=READ-ONLY, type=uint8
    gCFG_u8DriverSideWinSwType
      data Val: category=VALUE, sw-calibration-access=READ-ONLY, type=uint8
    gPRM_u8UINM_DriverSideWinSwActivetime
      data Val: category=VALUE, sw-calibration-access=READ-ONLY, type=uint8
    gPRM_u8UINM_LocalSideWinSwActivetime
      data Val: category=VALUE, sw-calibration-access=READ-ONLY, type=uint8
    gWND_u8DrvWinOutput
      data Val: category=VALUE, sw-calibration-access=READ-ONLY, type=uint8
    gWND_u8PsgWinOutput
      data Val: category=VALUE, sw-calibration-access=READ-ONLY, type=uint8
    gWND_u8RLWinOutput
      data Val: category=VALUE, sw-calibration-access=READ-ONLY, type=uint8
    gWND_u8RRWinOutput
      data Val: category=VALUE, sw-calibration-access=READ-ONLY, type=uint8
    gWND_u8DrvSideFLWinSwSt
      data Val: category=VALUE, sw-calibration-access=READ-ONLY, type=uint8
    gWND_u8DrvSideFRWinSwSt
      data Val: category=VALUE, sw-calibration-access=READ-ONLY, type=uint8
    gWND_u8DrvSideRLWinSwSt
      data Val: category=VALUE, sw-calibration-access=READ-ONLY, type=uint8
    gWND_u8DrvSideRRWinSwSt
      data Val: category=VALUE, sw-calibration-access=READ-ONLY, type=uint8
    gWND_u8LocalSideFRWinSwSt
      data Val: category=VALUE, sw-calibration-access=READ-ONLY, type=uint8
    gWND_u8LocalSideRLWinSwSt
      data Val: category=VALUE, sw-calibration-access=READ-ONLY, type=uint8
    gWND_u8LocalSideRRWinSwSt
      data Val: category=VALUE, sw-calibration-access=READ-ONLY, type=uint8
    gWND_u8CurrentFLWinPst
      data Val: category=VALUE, sw-calibration-access=READ-ONLY, type=uint8
    gWND_u8CurrentFRWinPst
      data Val: category=VALUE, sw-calibration-access=READ-ONLY, type=uint8
    gWND_u8CurrentRLWinPst
      data Val: category=VALUE, sw-calibration-access=READ-ONLY, type=uint8
    gWND_u8CurrentRRWinPst
      data Val: category=VALUE, sw-calibration-access=READ-ONLY, type=uint8
    gWin_u8FLOutputSts
      data Val: category=VALUE, sw-calibration-access=READ-ONLY, type=uint8
    gWin_u8FROutputSts
      data Val: category=VALUE, sw-calibration-access=READ-ONLY, type=uint8
    gWin_u8RLOutputSts
      data Val: category=VALUE, sw-calibration-access=READ-ONLY, type=uint8
    gWin_u8RROutputSts
      data Val: category=VALUE, sw-calibration-access=READ-ONLY, type=uint8
    gWND_bFLWinMotErrSt
      data Val: category=VALUE, sw-calibration-access=READ-ONLY, type=boolean
    gWND_bFRWinMotErrSt
      data Val: category=VALUE, sw-calibration-access=READ-ONLY, type=boolean
    gWND_bRLWinMotErrSt
      data Val: category=VALUE, sw-calibration-access=READ-ONLY, type=boolean
    gWND_bRRWinMotErrSt
      data Val: category=VALUE, sw-calibration-access=READ-ONLY, type=boolean
    gWND_u32AllowSleep_Local
      data Val: category=VALUE, sw-calibration-access=READ-ONLY, type=uint16
    gWND_u8Wakeup
      data Val: category=VALUE, sw-calibration-access=READ-ONLY, type=uint8
    gWND_u32AllowSleep_NW
      data Val: category=VALUE, sw-calibration-access=READ-ONLY, type=uint32
    gWND_bFLNormStartFlg
      data Val: category=VALUE, sw-calibration-access=READ-ONLY, type=boolean
    gWND_bFRNormStartFlg
      data Val: category=VALUE, sw-calibration-access=READ-ONLY, type=boolean
    gWND_bRLNormStartFlg
      data Val: category=VALUE, sw-calibration-access=READ-ONLY, type=boolean
    gWND_bRRNormStartFlg
      data Val: category=VALUE, sw-calibration-access=READ-ONLY, type=boolean
    gWND_bRLDoorOutsideSwSt
      data Val: category=VALUE, sw-calibration-access=READ-ONLY, type=boolean
    gWND_bRRDoorOutsideSwSt
      data Val: category=VALUE, sw-calibration-access=READ-ONLY, type=boolean
    gWND_bFRDoorOutsideSwSt
      data Val: category=VALUE, sw-calibration-access=READ-ONLY, type=boolean
    gWND_bFLDoorOutsideSwSt
      data Val: category=VALUE, sw-calibration-access=READ-ONLY, type=boolean
    gWin_bRLWinShortDropSt
      data Val: category=VALUE, sw-calibration-access=READ-ONLY, type=boolean
    gWin_bRRWinShortDropSt
      data Val: category=VALUE, sw-calibration-access=READ-ONLY, type=boolean
    gWin_bFRWinShortDropSt
      data Val: category=VALUE, sw-calibration-access=READ-ONLY, type=boolean
    gWin_bFLWinShortDropSt
      data Val: category=VALUE, sw-calibration-access=READ-ONLY, type=boolean
    gWin_bRLOutSideDoorSwFlg
      data Val: category=VALUE, sw-calibration-access=READ-ONLY, type=boolean
    gWin_bRROutSideDoorSwFlg
      data Val: category=VALUE, sw-calibration-access=READ-ONLY, type=boolean
    gWND_bFLUpOutputWinSt
      data Val: category=VALUE, sw-calibration-access=READ-ONLY, type=boolean
    gWND_bFRUpOutputWinSt
      data Val: category=VALUE, sw-calibration-access=READ-ONLY, type=boolean
    gWND_bRLUpOutputWinSt
      data Val: category=VALUE, sw-calibration-access=READ-ONLY, type=boolean
    gWND_bRRUpOutputWinSt
      data Val: category=VALUE, sw-calibration-access=READ-ONLY, type=boolean
    gWND_bFLDnOutputWinSt
      data Val: category=VALUE, sw-calibration-access=READ-ONLY, type=boolean
    gWND_bFRDnOutputWinSt
      data Val: category=VALUE, sw-calibration-access=READ-ONLY, type=boolean
    gWND_bRLDnOutputWinSt
      data Val: category=VALUE, sw-calibration-access=READ-ONLY, type=boolean
    gWND_bRRDnOutputWinSt
      data Val: category=VALUE, sw-calibration-access=READ-ONLY, type=boolean
    gWND_u8FLPositionSts
      data Val: category=VALUE, sw-calibration-access=READ-ONLY, type=uint8
    gWND_u8FRPositionSts
      data Val: category=VALUE, sw-calibration-access=READ-ONLY, type=uint8
    gWND_u8RLPositionSts
      data Val: category=VALUE, sw-calibration-access=READ-ONLY, type=uint8
    gWND_u8RRPositionSts
      data Val: category=VALUE, sw-calibration-access=READ-ONLY, type=uint8
    gWin_bFLOutSideDoorSwFlg
      data Val: category=VALUE, sw-calibration-access=READ-ONLY, type=boolean
    gWin_bFROutSideDoorSwFlg
      data Val: category=VALUE, sw-calibration-access=READ-ONLY, type=boolean
    gWin_u8FLWNDExecReq
      data Val: category=VALUE, sw-calibration-access=READ-ONLY, type=uint8
    gWin_u8FRWNDExecReq
      data Val: category=VALUE, sw-calibration-access=READ-ONLY, type=uint8
    gWin_u8RLWNDExecReq
      data Val: category=VALUE, sw-calibration-access=READ-ONLY, type=uint8
    gWin_u8RRWNDExecReq
      data Val: category=VALUE, sw-calibration-access=READ-ONLY, type=uint8
    gWin_bAllow_FLSPsleep
      data Val: category=VALUE, sw-calibration-access=READ-ONLY, type=boolean
    gWin_bAllow_FRSPsleep
      data Val: category=VALUE, sw-calibration-access=READ-ONLY, type=boolean
    gWin_bAllow_RLSPsleep
      data Val: category=VALUE, sw-calibration-access=READ-ONLY, type=boolean
    gWin_bAllow_RRSPsleep
      data Val: category=VALUE, sw-calibration-access=READ-ONLY, type=boolean
    gWin_bSpecialFlag_FL
      data Val: category=VALUE, sw-calibration-access=READ-ONLY, type=boolean
    gWin_bSpecialFlag_FR
      data Val: category=VALUE, sw-calibration-access=READ-ONLY, type=boolean
    gWin_bSpecialFlag_RL
      data Val: category=VALUE, sw-calibration-access=READ-ONLY, type=boolean
    gWin_bSpecialFlag_RR
      data Val: category=VALUE, sw-calibration-access=READ-ONLY, type=boolean
    gWin_u8FLWNDCmd
      data Val: category=VALUE, sw-calibration-access=READ-ONLY, type=uint8
    gWin_u8FRWNDCmd
      data Val: category=VALUE, sw-calibration-access=READ-ONLY, type=uint8
    gWin_u8RLWNDCmd
      data Val: category=VALUE, sw-calibration-access=READ-ONLY, type=uint8
    gWin_u8RRWNDCmd
      data Val: category=VALUE, sw-calibration-access=READ-ONLY, type=uint8
    gWin_u8FLWNDCmdSrc
      data Val: category=VALUE, sw-calibration-access=READ-ONLY, type=uint8
    gWin_u8FRWNDCmdSrc
      data Val: category=VALUE, sw-calibration-access=READ-ONLY, type=uint8
    gWin_u8RLWNDCmdSrc
      data Val: category=VALUE, sw-calibration-access=READ-ONLY, type=uint8
    gWin_u8RRWNDCmdSrc
      data Val: category=VALUE, sw-calibration-access=READ-ONLY, type=uint8
    gWin_bFLWinShrtDrpFlg
      data Val: category=VALUE, sw-calibration-access=READ-ONLY, type=boolean
    gWin_bFRWinShrtDrpFlg
      data Val: category=VALUE, sw-calibration-access=READ-ONLY, type=boolean
    gWin_bRLWinShrtDrpFlg
      data Val: category=VALUE, sw-calibration-access=READ-ONLY, type=boolean
    gWin_bRRWinShrtDrpFlg
      data Val: category=VALUE, sw-calibration-access=READ-ONLY, type=boolean
    gWND_bPsgWinLockBtnSt
      data Val: category=VALUE, sw-calibration-access=READ-ONLY, type=boolean
    gWin_u8PWL_WinOpeationSt_FLWinSt
      data Val: category=VALUE, sw-calibration-access=READ-ONLY, type=uint8
    gWin_u8PWL_WinOpeationSt_FRWinSt
      data Val: category=VALUE, sw-calibration-access=READ-ONLY, type=uint8
    gWin_u8PWL_WinOpeationSt_RLWinSt
      data Val: category=VALUE, sw-calibration-access=READ-ONLY, type=uint8
    gWin_u8PWL_WinOpeationSt_RRWinSt
      data Val: category=VALUE, sw-calibration-access=READ-ONLY, type=uint8
    gWin_bFLDelayAdjSpdFlg
      data Val: category=VALUE, sw-calibration-access=READ-ONLY, type=boolean
    gWin_bFRDelayAdjSpdFlg
      data Val: category=VALUE, sw-calibration-access=READ-ONLY, type=boolean
    gWin_bRLDelayAdjSpdFlg
      data Val: category=VALUE, sw-calibration-access=READ-ONLY, type=boolean
    gWin_bRRDelayAdjSpdFlg
      data Val: category=VALUE, sw-calibration-access=READ-ONLY, type=boolean
